VERSION ""

NS_ :

BS_:

BU_: ppt eps_batt eps_dist eps_gen adcs_rwz adcs_rwy adcs_rwx adcs_mtq rahs adcs_sensorproc adcs_mpc adcs_estim adcs_bdot com_1 com_2
VAL_TABLE_ mtq_phase 2 "pms_phase" 1 "actuation_phase" 0 "measurement_phase" ;
VAL_TABLE_ bdot_mag_mode 3 "sp2 mode" 2 "sp1 mode" 1 "bdot mode" 0 "auto mode" ;
VAL_TABLE_ bdot_control_mode 3 "spam" 2 "spam mag self test" 1 "sleep mode" 0 "normal mode" ;
VAL_TABLE_ domain_state 3 "off_batt_undervoltage" 2 "off_overcurrent" 1 "off_manual" 0 "on" ;
VAL_TABLE_ nbool 2 "null" 1 "true" 0 "false" ;
VAL_TABLE_ fire_state 3 "no discharge" 2 "no charge" 1 "fire overridden" 0 "fire successful" ;
VAL_TABLE_ uv_state 1 "undervoltage" 0 "normal" ;
VAL_TABLE_ mode 4 "low power" 3 "pointing" 1 "bdot" 0 "fsw off" ;
VAL_TABLE_ pwr_domain 8 "unk" 7 "com1" 6 "com2" 5 "rahs" 4 "bdot" 3 "estim" 2 "wheel" 1 "eps" 0 "ppt" ;
VAL_TABLE_ sat_state 1 "good" 0 "bad" ;
VAL_TABLE_ node 15 "rahs" 14 "com_2" 13 "com_1" 12 "adcs_mtq" 11 "adcs_sensorproc" 10 "adcs_mpc" 9 "adcs_estim" 8 "eps_batt" 7 "eps_gen" 6 "eps_dist" 5 "ppt" 4 "adcs_rwz" 3 "adcs_rwy" 2 "adcs_rwx" 1 "adcs_bdot" 0 "test" ;
VAL_TABLE_ agg 5 "sum" 4 "max" 3 "min" 2 "count" 1 "avg" 0 "none" ;
VAL_TABLE_ bool 1 "true" 0 "false" ;

BO_ 2449736399 gcmd_eps_batt_fulldef: 8 Vector__XXX
 SG_ gcmd_eps_batt_fulldef_const_volt : 0|32@1- (1,0) [0|8] "V" Vector__XXX
 SG_ gcmd_eps_batt_fulldef_chg_curr : 32|32@1- (1,0) [0|1] "Amps" Vector__XXX

BO_ 2452161116 rc_adcs_bdot_5: 6 Vector__XXX
 SG_ rc_adcs_bdot_5_last_spam_z_mtq_z : 32|16@1- (1,0) [-32768|32767] "1/73 nT" Vector__XXX
 SG_ rc_adcs_bdot_5_last_spam_z_mtq_y : 16|16@1- (1,0) [-32768|32767] "1/73 nT" Vector__XXX
 SG_ rc_adcs_bdot_5_last_spam_z_mtq_x : 0|16@1- (1,0) [-32768|32767] "1/73 nT" Vector__XXX

BO_ 2449736398 gcmd_reset_minmax: 0 Vector__XXX

BO_ 2452161134 rc_eps_batt_h2: 1 Vector__XXX
 SG_ rc_eps_batt_h2_canrxerror : 0|8@1+ (1,0) [0|255] "" Vector__XXX

BO_ 2452161133 rc_adcs_bdot_h2: 1 Vector__XXX
 SG_ rc_adcs_bdot_h2_canrxerror : 0|8@1+ (1,0) [0|255] "" Vector__XXX

BO_ 2452161132 rc_eps_dist_h2: 1 Vector__XXX
 SG_ rc_eps_dist_h2_canrxerror : 0|8@1+ (1,0) [0|255] "" Vector__XXX

BO_ 2452161131 rc_adcs_mpc_h2: 8 Vector__XXX
 SG_ rc_adcs_mpc_h2_canrxerror : 0|8@1+ (1,0) [0|255] "" Vector__XXX

BO_ 2452161130 rc_adcs_estim_h2: 1 Vector__XXX
 SG_ rc_adcs_estim_h2_canrxerror : 0|8@1+ (1,0) [0|255] "" Vector__XXX

BO_ 2452161129 rc_adcs_sp_h2: 1 Vector__XXX
 SG_ rc_adcs_sp_h2_canrxerror : 0|8@1+ (1,0) [0|255] "" Vector__XXX

BO_ 2452161128 rc_eps_gen_h2: 8 Vector__XXX
 SG_ rc_eps_gen_h2_canrxerror : 0|8@1+ (1,0) [0|255] "" Vector__XXX

BO_ 2452161127 rc_adcs_mtq_h2: 1 Vector__XXX
 SG_ rc_adcs_mtq_h2_canrxerror : 0|8@1+ (1,0) [0|255] "" Vector__XXX

BO_ 2452161126 rc_ppt_h2: 1 Vector__XXX
 SG_ rc_ppt_h2_canrxerror : 0|8@1+ (1,0) [0|255] "" Vector__XXX

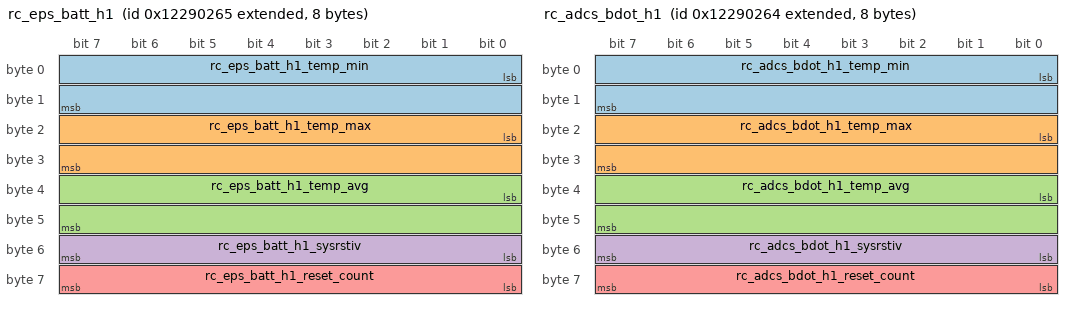
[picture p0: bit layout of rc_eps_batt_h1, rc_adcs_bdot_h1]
BO_ 2452161125 rc_eps_batt_h1: 8 Vector__XXX
 SG_ rc_eps_batt_h1_temp_min : 0|16@1- (1,0) [-32768|32767] "cC" Vector__XXX
 SG_ rc_eps_batt_h1_temp_max : 16|16@1- (1,0) [-32768|32767] "cC" Vector__XXX
 SG_ rc_eps_batt_h1_temp_avg : 32|16@1- (1,0) [-32768|32767] "cC" Vector__XXX
 SG_ rc_eps_batt_h1_sysrstiv : 48|8@1+ (1,0) [0|255] "" Vector__XXX
 SG_ rc_eps_batt_h1_reset_count : 56|8@1+ (1,0) [0|255] "" Vector__XXX

BO_ 2452161124 rc_adcs_bdot_h1: 8 Vector__XXX
 SG_ rc_adcs_bdot_h1_temp_min : 0|16@1- (1,0) [-32768|32767] "cC" Vector__XXX
 SG_ rc_adcs_bdot_h1_temp_max : 16|16@1- (1,0) [-32768|32767] "cC" Vector__XXX
 SG_ rc_adcs_bdot_h1_temp_avg : 32|16@1- (1,0) [-32768|32767] "cC" Vector__XXX
 SG_ rc_adcs_bdot_h1_sysrstiv : 48|8@1+ (1,0) [0|255] "" Vector__XXX
 SG_ rc_adcs_bdot_h1_reset_count : 56|8@1+ (1,0) [0|255] "" Vector__XXX

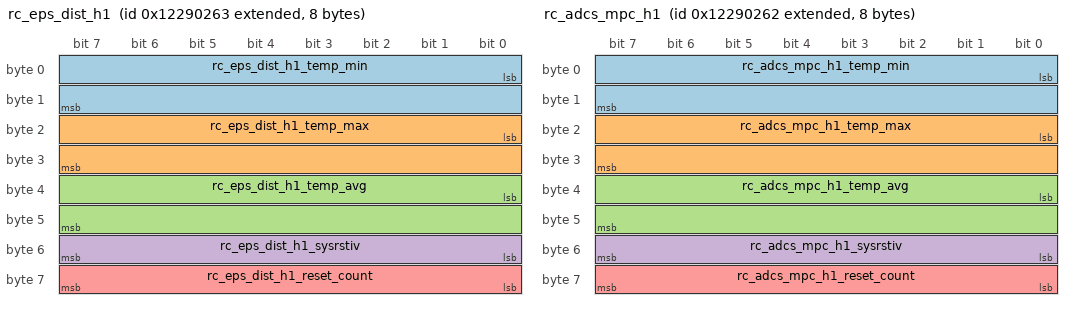
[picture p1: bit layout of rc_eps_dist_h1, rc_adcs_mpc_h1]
BO_ 2452161123 rc_eps_dist_h1: 8 Vector__XXX
 SG_ rc_eps_dist_h1_temp_min : 0|16@1- (1,0) [-32768|32767] "cC" Vector__XXX
 SG_ rc_eps_dist_h1_temp_max : 16|16@1- (1,0) [-32768|32767] "cC" Vector__XXX
 SG_ rc_eps_dist_h1_temp_avg : 32|16@1- (1,0) [-32768|32767] "cC" Vector__XXX
 SG_ rc_eps_dist_h1_sysrstiv : 48|8@1+ (1,0) [0|255] "" Vector__XXX
 SG_ rc_eps_dist_h1_reset_count : 56|8@1+ (1,0) [0|255] "" Vector__XXX

BO_ 2452161122 rc_adcs_mpc_h1: 8 Vector__XXX
 SG_ rc_adcs_mpc_h1_temp_min : 0|16@1- (1,0) [-32768|32767] "cC" Vector__XXX
 SG_ rc_adcs_mpc_h1_temp_max : 16|16@1- (1,0) [-32768|32767] "cC" Vector__XXX
 SG_ rc_adcs_mpc_h1_temp_avg : 32|16@1- (1,0) [-32768|32767] "cC" Vector__XXX
 SG_ rc_adcs_mpc_h1_sysrstiv : 48|8@1+ (1,0) [0|255] "" Vector__XXX
 SG_ rc_adcs_mpc_h1_reset_count : 56|8@1+ (1,0) [0|255] "" Vector__XXX

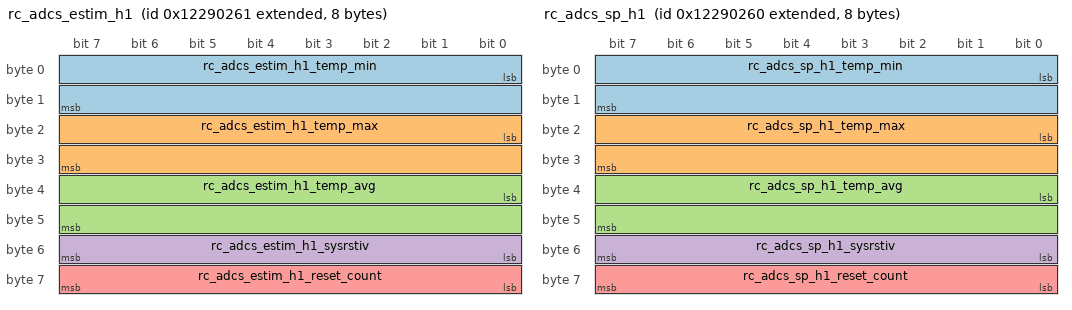
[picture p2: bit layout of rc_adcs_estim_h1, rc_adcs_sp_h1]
BO_ 2452161121 rc_adcs_estim_h1: 8 Vector__XXX
 SG_ rc_adcs_estim_h1_temp_min : 0|16@1- (1,0) [-32768|32767] "cC" Vector__XXX
 SG_ rc_adcs_estim_h1_temp_max : 16|16@1- (1,0) [-32768|32767] "cC" Vector__XXX
 SG_ rc_adcs_estim_h1_temp_avg : 32|16@1- (1,0) [-32768|32767] "cC" Vector__XXX
 SG_ rc_adcs_estim_h1_sysrstiv : 48|8@1+ (1,0) [0|255] "" Vector__XXX
 SG_ rc_adcs_estim_h1_reset_count : 56|8@1+ (1,0) [0|255] "" Vector__XXX

BO_ 2452161120 rc_adcs_sp_h1: 8 Vector__XXX
 SG_ rc_adcs_sp_h1_temp_min : 0|16@1- (1,0) [-32768|32767] "cC" Vector__XXX
 SG_ rc_adcs_sp_h1_temp_max : 16|16@1- (1,0) [-32768|32767] "cC" Vector__XXX
 SG_ rc_adcs_sp_h1_temp_avg : 32|16@1- (1,0) [-32768|32767] "cC" Vector__XXX
 SG_ rc_adcs_sp_h1_sysrstiv : 48|8@1+ (1,0) [0|255] "" Vector__XXX
 SG_ rc_adcs_sp_h1_reset_count : 56|8@1+ (1,0) [0|255] "" Vector__XXX

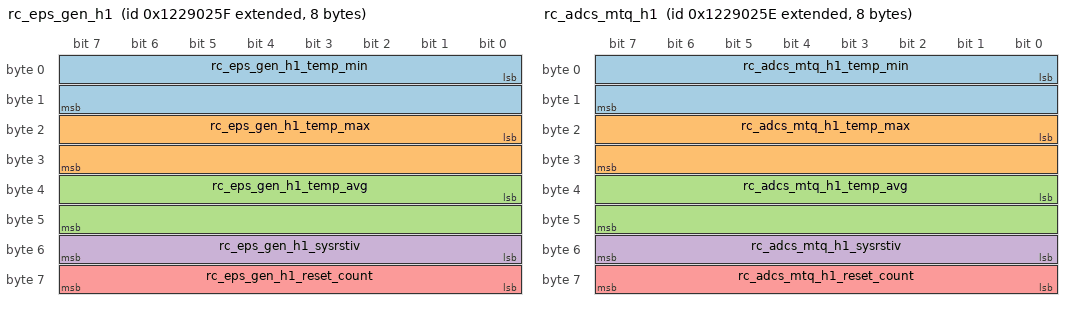
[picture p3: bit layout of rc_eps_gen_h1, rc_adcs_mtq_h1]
BO_ 2452161119 rc_eps_gen_h1: 8 Vector__XXX
 SG_ rc_eps_gen_h1_temp_min : 0|16@1- (1,0) [-32768|32767] "cC" Vector__XXX
 SG_ rc_eps_gen_h1_temp_max : 16|16@1- (1,0) [-32768|32767] "cC" Vector__XXX
 SG_ rc_eps_gen_h1_temp_avg : 32|16@1- (1,0) [-32768|32767] "cC" Vector__XXX
 SG_ rc_eps_gen_h1_sysrstiv : 48|8@1+ (1,0) [0|255] "" Vector__XXX
 SG_ rc_eps_gen_h1_reset_count : 56|8@1+ (1,0) [0|255] "" Vector__XXX

BO_ 2452161118 rc_adcs_mtq_h1: 8 Vector__XXX
 SG_ rc_adcs_mtq_h1_temp_min : 0|16@1- (1,0) [-32768|32767] "cC" Vector__XXX
 SG_ rc_adcs_mtq_h1_temp_max : 16|16@1- (1,0) [-32768|32767] "cC" Vector__XXX
 SG_ rc_adcs_mtq_h1_temp_avg : 32|16@1- (1,0) [-32768|32767] "cC" Vector__XXX
 SG_ rc_adcs_mtq_h1_sysrstiv : 48|8@1+ (1,0) [0|255] "" Vector__XXX
 SG_ rc_adcs_mtq_h1_reset_count : 56|8@1+ (1,0) [0|255] "" Vector__XXX

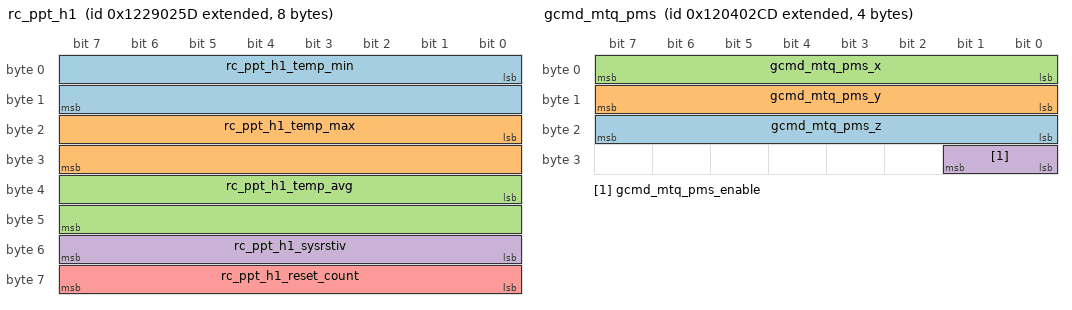
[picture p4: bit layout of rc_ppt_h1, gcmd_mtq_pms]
BO_ 2452161117 rc_ppt_h1: 8 Vector__XXX
 SG_ rc_ppt_h1_temp_min : 0|16@1- (1,0) [-32768|32767] "cC" Vector__XXX
 SG_ rc_ppt_h1_temp_max : 16|16@1- (1,0) [-32768|32767] "cC" Vector__XXX
 SG_ rc_ppt_h1_temp_avg : 32|16@1- (1,0) [-32768|32767] "cC" Vector__XXX
 SG_ rc_ppt_h1_sysrstiv : 48|8@1+ (1,0) [0|255] "" Vector__XXX
 SG_ rc_ppt_h1_reset_count : 56|8@1+ (1,0) [0|255] "" Vector__XXX

BO_ 2449736397 gcmd_mtq_pms: 4 Vector__XXX
 SG_ gcmd_mtq_pms_z : 16|8@1- (1,0) [-100|100] "" Vector__XXX
 SG_ gcmd_mtq_pms_y : 8|8@1- (1,0) [-100|100] "" Vector__XXX
 SG_ gcmd_mtq_pms_x : 0|8@1- (1,0) [-100|100] "" Vector__XXX
 SG_ gcmd_mtq_pms_enable : 24|2@1+ (1,0) [0|2] "" Vector__XXX

BO_ 2449736396 gcmd_bdot_max_tumble: 2 Vector__XXX
 SG_ gcmd_bdot_max_tumble_time : 0|16@1+ (1,0) [0|65535] "minutes" Vector__XXX

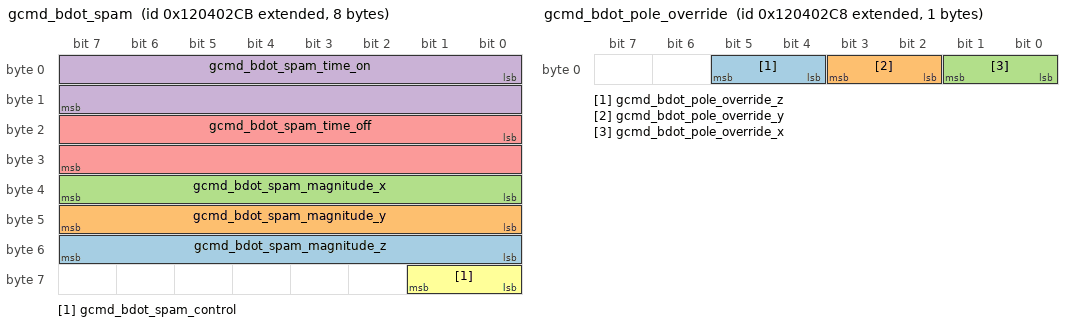
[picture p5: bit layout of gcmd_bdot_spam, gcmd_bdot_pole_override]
BO_ 2449736395 gcmd_bdot_spam: 8 Vector__XXX
 SG_ gcmd_bdot_spam_magnitude_z : 48|8@1- (1,0) [-100|100] "" Vector__XXX
 SG_ gcmd_bdot_spam_magnitude_y : 40|8@1- (1,0) [-100|100] "" Vector__XXX
 SG_ gcmd_bdot_spam_magnitude_x : 32|8@1- (1,0) [-100|100] "" Vector__XXX
 SG_ gcmd_bdot_spam_time_on : 0|16@1+ (1,0) [0|65535] "minutes" Vector__XXX
 SG_ gcmd_bdot_spam_time_off : 16|16@1+ (1,0) [0|65535] "minutes" Vector__XXX
 SG_ gcmd_bdot_spam_control : 56|2@1+ (1,0) [0|2] "" Vector__XXX

BO_ 2449736394 gcmd_bdot_control: 1 Vector__XXX
 SG_ gcmd_bdot_control_mode : 0|2@1+ (1,0) [0|3] "" Vector__XXX

BO_ 2449736393 gcmd_bdot_mag_control: 1 Vector__XXX
 SG_ gcmd_bdot_mag_control_mode : 0|2@1+ (1,0) [0|3] "" Vector__XXX

BO_ 2449736392 gcmd_bdot_pole_override: 1 Vector__XXX
 SG_ gcmd_bdot_pole_override_z : 4|2@1+ (1,0) [0|2] "" Vector__XXX
 SG_ gcmd_bdot_pole_override_y : 2|2@1+ (1,0) [0|2] "" Vector__XXX
 SG_ gcmd_bdot_pole_override_x : 0|2@1+ (1,0) [0|2] "" Vector__XXX

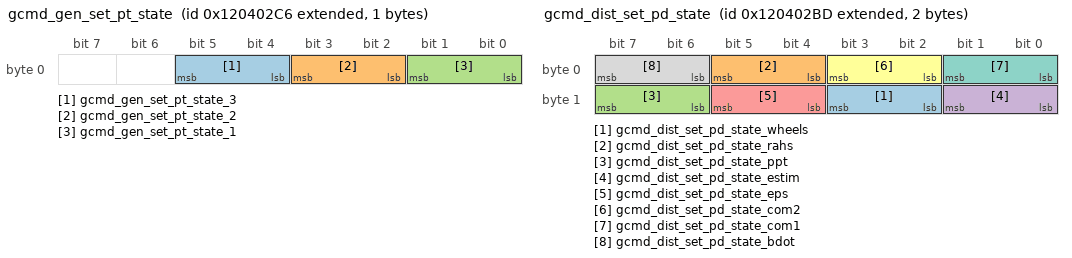
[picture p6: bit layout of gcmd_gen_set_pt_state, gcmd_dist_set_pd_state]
BO_ 2449736390 gcmd_gen_set_pt_state: 1 Vector__XXX
 SG_ gcmd_gen_set_pt_state_3 : 4|2@1+ (1,0) [0|3] "" Vector__XXX
 SG_ gcmd_gen_set_pt_state_2 : 2|2@1+ (1,0) [0|3] "" Vector__XXX
 SG_ gcmd_gen_set_pt_state_1 : 0|2@1+ (1,0) [0|3] "" Vector__XXX

BO_ 2449736391 gcmd_sp_set_thresh: 1 Vector__XXX
 SG_ gcmd_sp_set_thresh_thresh : 0|16@1+ (1,0) [0|65535] "1/73 nanoTeslas" Vector__XXX

BO_ 2449736389 gcmd_dist_set_pd_ovc_ppt: 4 Vector__XXX
 SG_ gcmd_dist_set_pd_ovc_ppt_ovc : 0|32@1- (1,0) [0|15] "A" Vector__XXX

BO_ 2449736388 gcmd_dist_set_pd_ovc_eps: 4 Vector__XXX
 SG_ gcmd_dist_set_pd_ovc_eps_ovc : 0|32@1- (1,0) [0|15] "A" Vector__XXX

BO_ 2449736387 gcmd_dist_set_pd_ovc_wheels: 4 Vector__XXX
 SG_ gcmd_dist_set_pd_ovc_wheels_ovc : 0|32@1- (1,0) [0|15] "A" Vector__XXX

BO_ 2449736386 gcmd_dist_set_pd_ovc_estim: 4 Vector__XXX
 SG_ gcmd_dist_set_pd_ovc_estim_ovc : 0|32@1- (1,0) [0|15] "A" Vector__XXX

BO_ 2449736385 gcmd_dist_set_pd_ovc_bdot: 4 Vector__XXX
 SG_ gcmd_dist_set_pd_ovc_bdot_ovc : 0|32@1- (1,0) [0|15] "A" Vector__XXX

BO_ 2449736384 gcmd_dist_set_pd_ovc_rahs: 4 Vector__XXX
 SG_ gcmd_dist_set_pd_ovc_rahs_ovc : 0|32@1- (1,0) [0|15] "A" Vector__XXX

BO_ 2449736383 gcmd_dist_set_pd_ovc_com2: 4 Vector__XXX
 SG_ gcmd_dist_set_pd_ovc_com2_ovc : 0|32@1- (1,0) [0|15] "A" Vector__XXX

BO_ 2449736382 gcmd_dist_set_pd_ovc_com1: 4 Vector__XXX
 SG_ gcmd_dist_set_pd_ovc_com1_ovc : 0|32@1- (1,0) [0|15] "A" Vector__XXX

BO_ 2449736381 gcmd_dist_set_pd_state: 2 Vector__XXX
 SG_ gcmd_dist_set_pd_state_wheels : 10|2@1+ (1,0) [0|3] "" Vector__XXX
 SG_ gcmd_dist_set_pd_state_rahs : 4|2@1+ (1,0) [0|3] "" Vector__XXX
 SG_ gcmd_dist_set_pd_state_ppt : 14|2@1+ (1,0) [0|3] "" Vector__XXX
 SG_ gcmd_dist_set_pd_state_estim : 8|2@1+ (1,0) [0|3] "" Vector__XXX
 SG_ gcmd_dist_set_pd_state_eps : 12|2@1+ (1,0) [0|3] "" Vector__XXX
 SG_ gcmd_dist_set_pd_state_com2 : 2|2@1+ (1,0) [0|3] "" Vector__XXX
 SG_ gcmd_dist_set_pd_state_com1 : 0|2@1+ (1,0) [0|3] "" Vector__XXX
 SG_ gcmd_dist_set_pd_state_bdot : 6|2@1+ (1,0) [0|3] "" Vector__XXX

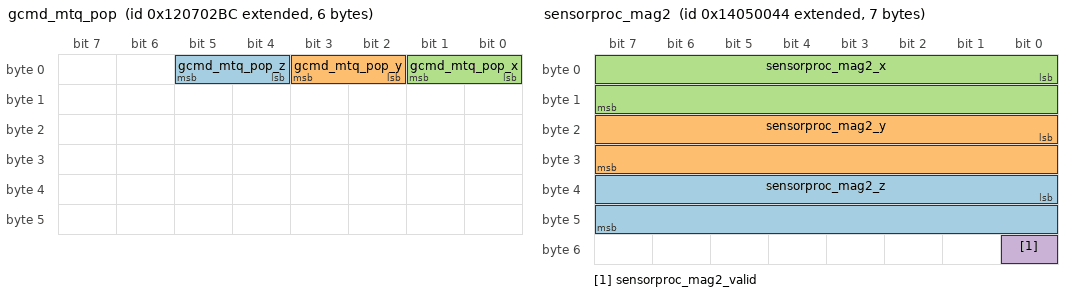
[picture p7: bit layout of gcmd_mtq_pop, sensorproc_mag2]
BO_ 2449932988 gcmd_mtq_pop: 6 Vector__XXX
 SG_ gcmd_mtq_pop_z : 4|2@1+ (1,0) [0|2] "" Vector__XXX
 SG_ gcmd_mtq_pop_y : 2|2@1+ (1,0) [0|2] "" Vector__XXX
 SG_ gcmd_mtq_pop_x : 0|2@1+ (1,0) [0|2] "" Vector__XXX

BO_ 2452161114 rc_eps_batt_7: 6 Vector__XXX
 SG_ rc_eps_batt_7_acc_charge_min : 0|16@1+ (1,0) [0|65535] "22.588 mAh" Vector__XXX
 SG_ rc_eps_batt_7_acc_charge_max : 16|16@1+ (1,0) [0|65535] "22.588 mAh" Vector__XXX
 SG_ rc_eps_batt_7_acc_charge_avg : 32|16@1+ (1,0) [0|65535] "22.588 mAh" Vector__XXX

BO_ 2483355716 sensorproc_mag2: 7 Vector__XXX
 SG_ sensorproc_mag2_z : 32|16@1- (1,0) [-32768|32767] "73 nanoTeslas" Vector__XXX
 SG_ sensorproc_mag2_y : 16|16@1- (1,0) [-32768|32767] "73 nanoTeslas" Vector__XXX
 SG_ sensorproc_mag2_x : 0|16@1- (1,0) [-32768|32767] "73 nanoTeslas" Vector__XXX
 SG_ sensorproc_mag2_valid : 48|1@1+ (1,0) [0|1] "bool" Vector__XXX

BO_ 2452161113 rc_adcs_estim_14: 8 Vector__XXX
 SG_ rc_adcs_estim_14_mag_z : 0|64@1- (1,0) [-1|1] "u" Vector__XXX

BO_ 2452161112 rc_adcs_estim_13: 8 Vector__XXX
 SG_ rc_adcs_estim_13_mag_y : 0|64@1- (1,0) [-1|1] "u" Vector__XXX

BO_ 2452161111 rc_adcs_estim_12: 8 Vector__XXX
 SG_ rc_adcs_estim_12_mag_x : 0|64@1- (1,0) [-1|1] "u" Vector__XXX

BO_ 2452161110 rc_adcs_estim_11: 8 Vector__XXX
 SG_ rc_adcs_estim_11_sun_z : 0|64@1- (1,0) [-1|1] "u" Vector__XXX

BO_ 2452161109 rc_adcs_estim_10: 8 Vector__XXX
 SG_ rc_adcs_estim_10_sun_y : 0|64@1- (1,0) [-1|1] "u" Vector__XXX

BO_ 2452161108 rc_adcs_estim_9: 8 Vector__XXX
 SG_ rc_adcs_estim_9_sun_x : 0|64@1- (1,0) [-1|1] "u" Vector__XXX

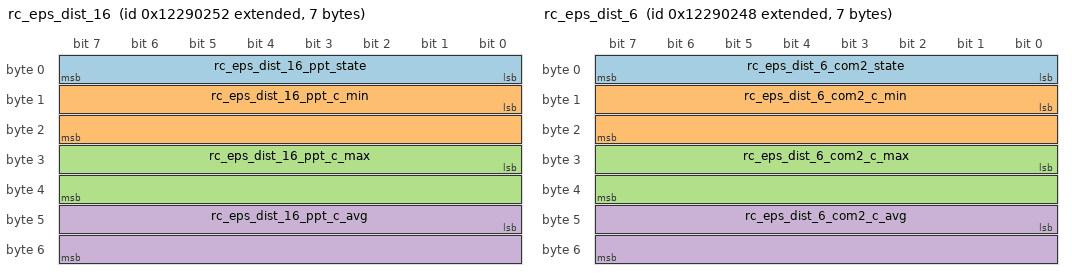
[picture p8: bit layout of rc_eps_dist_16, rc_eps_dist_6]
BO_ 2452161106 rc_eps_dist_16: 7 Vector__XXX
 SG_ rc_eps_dist_16_ppt_state : 0|8@1+ (1,0) [0|3] "" Vector__XXX
 SG_ rc_eps_dist_16_ppt_c_min : 8|16@1- (1,0) [-32768|32767] "raw node current dist" Vector__XXX
 SG_ rc_eps_dist_16_ppt_c_max : 24|16@1- (1,0) [-32768|32767] "raw node current dist" Vector__XXX
 SG_ rc_eps_dist_16_ppt_c_avg : 40|16@1- (1,0) [-32768|32767] "raw node current dist" Vector__XXX

BO_ 2452161099 rc_eps_dist_9: 6 Vector__XXX
 SG_ rc_eps_dist_9_rahs_v_min : 0|16@1+ (1,0) [0|65535] "raw node voltage" Vector__XXX
 SG_ rc_eps_dist_9_rahs_v_max : 16|16@1+ (1,0) [0|65535] "raw node voltage" Vector__XXX
 SG_ rc_eps_dist_9_rahs_v_avg : 32|16@1+ (1,0) [0|65535] "raw node voltage" Vector__XXX

BO_ 2452161097 rc_eps_dist_7: 6 Vector__XXX
 SG_ rc_eps_dist_7_com2_v_min : 0|16@1+ (1,0) [0|65535] "raw node voltage" Vector__XXX
 SG_ rc_eps_dist_7_com2_v_max : 16|16@1+ (1,0) [0|65535] "raw node voltage" Vector__XXX
 SG_ rc_eps_dist_7_com2_v_avg : 32|16@1+ (1,0) [0|65535] "raw node voltage" Vector__XXX

BO_ 2452161096 rc_eps_dist_6: 7 Vector__XXX
 SG_ rc_eps_dist_6_com2_state : 0|8@1+ (1,0) [0|3] "" Vector__XXX
 SG_ rc_eps_dist_6_com2_c_min : 8|16@1- (1,0) [-32768|32767] "raw node current dist" Vector__XXX
 SG_ rc_eps_dist_6_com2_c_max : 24|16@1- (1,0) [-32768|32767] "raw node current dist" Vector__XXX
 SG_ rc_eps_dist_6_com2_c_avg : 40|16@1- (1,0) [-32768|32767] "raw node current dist" Vector__XXX

BO_ 2452161095 rc_eps_dist_5: 6 Vector__XXX
 SG_ rc_eps_dist_5_com1_v_min : 0|16@1+ (1,0) [0|65535] "raw node voltage" Vector__XXX
 SG_ rc_eps_dist_5_com1_v_max : 16|16@1+ (1,0) [0|65535] "raw node voltage" Vector__XXX
 SG_ rc_eps_dist_5_com1_v_avg : 32|16@1+ (1,0) [0|65535] "raw node voltage" Vector__XXX

BO_ 2452161093 rc_eps_dist_3: 6 Vector__XXX
 SG_ rc_eps_dist_3_batt_v_avg : 32|16@1+ (1,0) [0|65535] "raw dist battery voltage" Vector__XXX
 SG_ rc_eps_dist_3_batt_v_max : 16|16@1+ (1,0) [0|65535] "raw dist battery voltage" Vector__XXX
 SG_ rc_eps_dist_3_batt_v_min : 0|16@1+ (1,0) [0|65535] "raw dist battery voltage" Vector__XXX

BO_ 2452161092 rc_eps_dist_2: 6 Vector__XXX
 SG_ rc_eps_dist_2_uv_state : 0|8@1+ (1,0) [0|3] "" Vector__XXX
 SG_ rc_eps_dist_2_met_overflow : 40|8@1+ (1,0) [0|255] "" Vector__XXX
 SG_ rc_eps_dist_2_met : 8|32@1+ (1,0) [0|4294967296] "2^-8 s" Vector__XXX

BO_ 2452161107 rc_eps_dist_17: 6 Vector__XXX
 SG_ rc_eps_dist_17_ppt_v_min : 0|16@1+ (1,0) [0|65535] "raw node voltage" Vector__XXX
 SG_ rc_eps_dist_17_ppt_v_max : 16|16@1+ (1,0) [0|65535] "raw node voltage" Vector__XXX
 SG_ rc_eps_dist_17_ppt_v_avg : 32|16@1+ (1,0) [0|65535] "raw node voltage" Vector__XXX

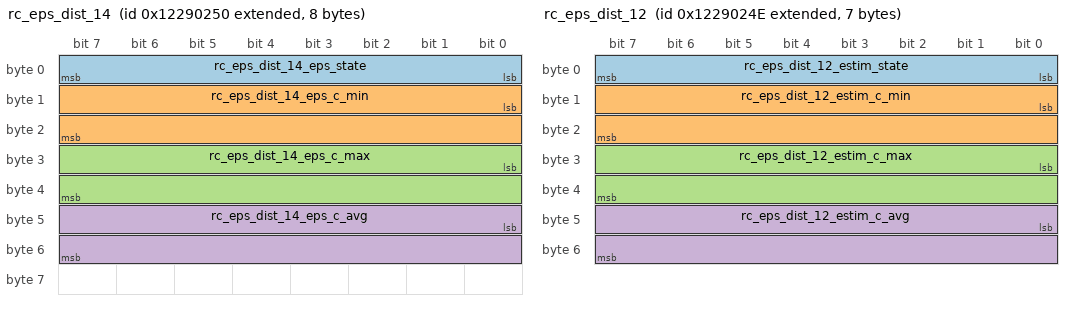
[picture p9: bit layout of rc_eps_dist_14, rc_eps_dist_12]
BO_ 2452161104 rc_eps_dist_14: 8 Vector__XXX
 SG_ rc_eps_dist_14_eps_state : 0|8@1+ (1,0) [0|3] "" Vector__XXX
 SG_ rc_eps_dist_14_eps_c_min : 8|16@1- (1,0) [-32768|32767] "raw node current dist" Vector__XXX
 SG_ rc_eps_dist_14_eps_c_max : 24|16@1- (1,0) [-32768|32767] "raw node current dist" Vector__XXX
 SG_ rc_eps_dist_14_eps_c_avg : 40|16@1- (1,0) [-32768|32767] "raw node current dist" Vector__XXX

BO_ 2452161103 rc_eps_dist_13: 6 Vector__XXX
 SG_ rc_eps_dist_13_estim_v_min : 0|16@1+ (1,0) [0|65535] "raw node voltage" Vector__XXX
 SG_ rc_eps_dist_13_estim_v_max : 16|16@1+ (1,0) [0|65535] "raw node voltage" Vector__XXX
 SG_ rc_eps_dist_13_estim_v_avg : 32|16@1+ (1,0) [0|65535] "raw node voltage" Vector__XXX

BO_ 2452161101 rc_eps_dist_11: 6 Vector__XXX
 SG_ rc_eps_dist_11_bdot_v_min : 0|16@1+ (1,0) [0|65535] "raw node voltage" Vector__XXX
 SG_ rc_eps_dist_11_bdot_v_max : 16|16@1+ (1,0) [0|65535] "raw node voltage" Vector__XXX
 SG_ rc_eps_dist_11_bdot_v_avg : 32|16@1+ (1,0) [0|65535] "raw node voltage" Vector__XXX

BO_ 2452161102 rc_eps_dist_12: 7 Vector__XXX
 SG_ rc_eps_dist_12_estim_state : 0|8@1+ (1,0) [0|3] "" Vector__XXX
 SG_ rc_eps_dist_12_estim_c_min : 8|16@1- (1,0) [-32768|32767] "raw node current dist" Vector__XXX
 SG_ rc_eps_dist_12_estim_c_max : 24|16@1- (1,0) [-32768|32767] "raw node current dist" Vector__XXX
 SG_ rc_eps_dist_12_estim_c_avg : 40|16@1- (1,0) [-32768|32767] "raw node current dist" Vector__XXX

BO_ 2452161105 rc_eps_dist_15: 6 Vector__XXX
 SG_ rc_eps_dist_15_eps_v_min : 0|16@1+ (1,0) [0|65535] "raw node voltage" Vector__XXX
 SG_ rc_eps_dist_15_eps_v_max : 16|16@1+ (1,0) [0|65535] "raw node voltage" Vector__XXX
 SG_ rc_eps_dist_15_eps_v_avg : 32|16@1+ (1,0) [0|65535] "raw node voltage" Vector__XXX

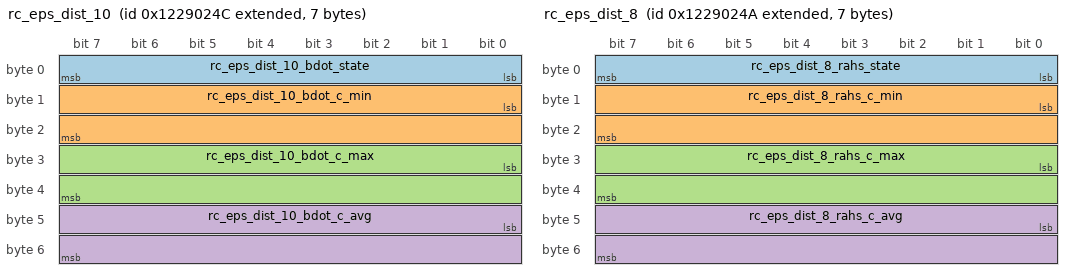
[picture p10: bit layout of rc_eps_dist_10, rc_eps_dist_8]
BO_ 2452161100 rc_eps_dist_10: 7 Vector__XXX
 SG_ rc_eps_dist_10_bdot_state : 0|8@1+ (1,0) [0|3] "" Vector__XXX
 SG_ rc_eps_dist_10_bdot_c_min : 8|16@1- (1,0) [-32768|32767] "raw node current dist" Vector__XXX
 SG_ rc_eps_dist_10_bdot_c_max : 24|16@1- (1,0) [-32768|32767] "raw node current dist" Vector__XXX
 SG_ rc_eps_dist_10_bdot_c_avg : 40|16@1- (1,0) [-32768|32767] "raw node current dist" Vector__XXX

BO_ 2452161098 rc_eps_dist_8: 7 Vector__XXX
 SG_ rc_eps_dist_8_rahs_state : 0|8@1+ (1,0) [0|3] "" Vector__XXX
 SG_ rc_eps_dist_8_rahs_c_min : 8|16@1- (1,0) [-32768|32767] "raw node current dist" Vector__XXX
 SG_ rc_eps_dist_8_rahs_c_max : 24|16@1- (1,0) [-32768|32767] "raw node current dist" Vector__XXX
 SG_ rc_eps_dist_8_rahs_c_avg : 40|16@1- (1,0) [-32768|32767] "raw node current dist" Vector__XXX

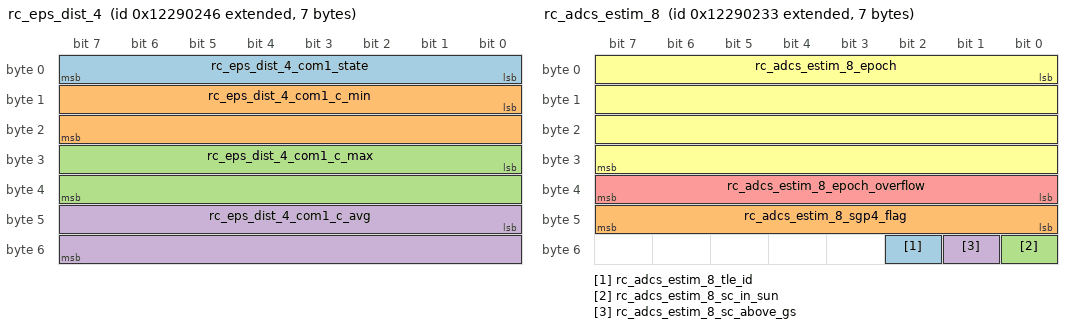
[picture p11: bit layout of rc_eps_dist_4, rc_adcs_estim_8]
BO_ 2452161094 rc_eps_dist_4: 7 Vector__XXX
 SG_ rc_eps_dist_4_com1_state : 0|8@1+ (1,0) [0|3] "" Vector__XXX
 SG_ rc_eps_dist_4_com1_c_min : 8|16@1- (1,0) [-32768|32767] "raw node current dist" Vector__XXX
 SG_ rc_eps_dist_4_com1_c_max : 24|16@1- (1,0) [-32768|32767] "raw node current dist" Vector__XXX
 SG_ rc_eps_dist_4_com1_c_avg : 40|16@1- (1,0) [-32768|32767] "raw node current dist" Vector__XXX

BO_ 2452161091 rc_eps_dist_1: 8 Vector__XXX

BO_ 2452161086 rc_adcs_mpc_11: 8 Vector__XXX
 SG_ rc_adcs_mpc_11_omega_z : 0|64@1- (1,0) [-10|10] "r/s" Vector__XXX

BO_ 2452161082 rc_adcs_mpc_7: 8 Vector__XXX
 SG_ rc_adcs_mpc_7_omega_max : 0|64@1- (1,0) [0|10] "r/s" Vector__XXX

BO_ 2452161083 rc_adcs_mpc_8: 8 Vector__XXX
 SG_ rc_adcs_mpc_8_omega_avg : 0|64@1- (1,0) [0|10] "r/s" Vector__XXX

BO_ 2452161084 rc_adcs_mpc_9: 8 Vector__XXX
 SG_ rc_adcs_mpc_9_omega_x : 0|64@1- (1,0) [-10|10] "r/s" Vector__XXX

BO_ 2452161080 rc_adcs_mpc_5: 8 Vector__XXX
 SG_ rc_adcs_mpc_5_sc_quat_4 : 0|64@1- (1,0) [-1|1] "u" Vector__XXX

BO_ 2452161081 rc_adcs_mpc_6: 8 Vector__XXX
 SG_ rc_adcs_mpc_6_omega_min : 0|64@1- (1,0) [0|10] "r/s" Vector__XXX

BO_ 2452161079 rc_adcs_mpc_4: 8 Vector__XXX
 SG_ rc_adcs_mpc_4_sc_quat_3 : 0|64@1- (1,0) [-1|1] "u" Vector__XXX

BO_ 2452161078 rc_adcs_mpc_3: 8 Vector__XXX
 SG_ rc_adcs_mpc_3_sc_quat_2 : 0|64@1- (1,0) [-1|1] "u" Vector__XXX

BO_ 2452161090 rc_adcs_mpc_15: 2 Vector__XXX
 SG_ rc_adcs_mpc_15_sc_mode : 0|8@1+ (1,0) [0|32] "" Vector__XXX
 SG_ rc_adcs_mpc_15_point_true : 8|8@1+ (1,0) [0|255] "" Vector__XXX

BO_ 2452161087 rc_adcs_mpc_12: 8 Vector__XXX

BO_ 2452161088 rc_adcs_mpc_13: 8 Vector__XXX

BO_ 2452161089 rc_adcs_mpc_14: 8 Vector__XXX

BO_ 2452161085 rc_adcs_mpc_10: 8 Vector__XXX
 SG_ rc_adcs_mpc_10_omega_y : 0|64@1- (1,0) [-10|10] "r/s" Vector__XXX

BO_ 2452161077 rc_adcs_mpc_2: 8 Vector__XXX
 SG_ rc_adcs_mpc_2_sc_quat_1 : 0|64@1- (1,0) [-1|1] "u" Vector__XXX

BO_ 2452161076 rc_adcs_mpc_1: 8 Vector__XXX

BO_ 2452161075 rc_adcs_estim_8: 7 Vector__XXX
 SG_ rc_adcs_estim_8_tle_id : 50|1@1+ (1,0) [0|1] "" Vector__XXX
 SG_ rc_adcs_estim_8_sgp4_flag : 40|8@1- (1,0) [-1|1] "" Vector__XXX
 SG_ rc_adcs_estim_8_sc_in_sun : 48|1@1+ (1,0) [0|1] "" Vector__XXX
 SG_ rc_adcs_estim_8_sc_above_gs : 49|1@1+ (1,0) [0|1] "" Vector__XXX
 SG_ rc_adcs_estim_8_epoch_overflow : 32|8@1+ (1,0) [0|255] "" Vector__XXX
 SG_ rc_adcs_estim_8_epoch : 0|32@1+ (1,0) [0|4294967295] "2^-8 s" Vector__XXX

BO_ 2452161074 rc_adcs_estim_7: 8 Vector__XXX
 SG_ rc_adcs_estim_7_vel_z : 0|64@1- (1,0) [-1.7E+308|1.7E+308] "m/s" Vector__XXX

BO_ 2452161073 rc_adcs_estim_6: 8 Vector__XXX
 SG_ rc_adcs_estim_6_vel_y : 0|64@1- (1,0) [-1.7E+308|1.7E+308] "m/s" Vector__XXX

BO_ 2452161072 rc_adcs_estim_5: 8 Vector__XXX
 SG_ rc_adcs_estim_5_vel_x : 0|64@1- (1,0) [-1.7E+308|1.7E+308] "m/s" Vector__XXX

BO_ 2452161071 rc_adcs_estim_4: 8 Vector__XXX
 SG_ rc_adcs_estim_4_pos_z : 0|64@1- (1,0) [-7000000|7000000] "m" Vector__XXX

BO_ 2452161069 rc_adcs_estim_2: 8 Vector__XXX
 SG_ rc_adcs_estim_2_pos_x : 0|64@1- (1,0) [-7000000|7000000] "m" Vector__XXX

BO_ 2452161070 rc_adcs_estim_3: 8 Vector__XXX
 SG_ rc_adcs_estim_3_pos_y : 0|64@1- (1,0) [-7000000|7000000] "m" Vector__XXX

BO_ 2452161068 rc_adcs_estim_1: 8 Vector__XXX

BO_ 2452161062 rc_adcs_sp_12: 8 Vector__XXX
 SG_ rc_adcs_sp_12_mag2_z_min : 32|16@1- (1,0) [-32768|32767] "73 nanoTeslas" Vector__XXX
 SG_ rc_adcs_sp_12_mag2_z_max : 48|16@1- (1,0) [-32768|32767] "73 nanoTeslas" Vector__XXX
 SG_ rc_adcs_sp_12_mag2_y_max : 0|16@1- (1,0) [-32768|32767] "73 nanoTeslas" Vector__XXX
 SG_ rc_adcs_sp_12_mag2_y_avg : 16|16@1- (1,0) [-32768|32767] "73 nanoTeslas" Vector__XXX

BO_ 2452161061 rc_adcs_sp_11: 8 Vector__XXX
 SG_ rc_adcs_sp_11_mag2_x_avg : 32|16@1- (1,0) [-32768|32767] "73 nanoTeslas" Vector__XXX
 SG_ rc_adcs_sp_11_mag2_x_max : 16|16@1- (1,0) [-32768|32767] "73 nanoTeslas" Vector__XXX
 SG_ rc_adcs_sp_11_mag2_x_min : 0|16@1- (1,0) [-32768|32767] "73 nanoTeslas" Vector__XXX
 SG_ rc_adcs_sp_11_mag2_y_min : 48|16@1- (1,0) [-32768|32767] "73 nanoTeslas" Vector__XXX

BO_ 2452161057 rc_adcs_sp_7: 8 Vector__XXX

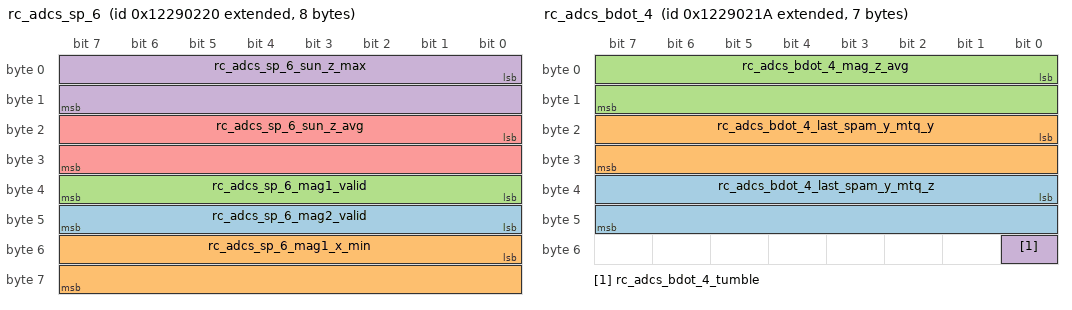
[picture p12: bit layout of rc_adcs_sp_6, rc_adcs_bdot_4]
BO_ 2452161056 rc_adcs_sp_6: 8 Vector__XXX
 SG_ rc_adcs_sp_6_mag2_valid : 40|8@1+ (1,0) [0|255] "" Vector__XXX
 SG_ rc_adcs_sp_6_mag1_x_min : 48|16@1- (1,0) [-32768|32767] "73 nanoTeslas" Vector__XXX
 SG_ rc_adcs_sp_6_mag1_valid : 32|8@1+ (1,0) [0|255] "" Vector__XXX
 SG_ rc_adcs_sp_6_sun_z_max : 0|16@1- (1,0) [-32768|32767] "1/32768 units" Vector__XXX
 SG_ rc_adcs_sp_6_sun_z_avg : 16|16@1- (1,0) [-32768|32767] "1/32768 units" Vector__XXX

BO_ 2452161067 rc_adcs_sp_17: 8 Vector__XXX
 SG_ rc_adcs_sp_17_imu_z_max : 0|16@1- (1,0) [-32768|32767] "0.004375 deg/s" Vector__XXX
 SG_ rc_adcs_sp_17_imu_z_avg : 16|16@1- (1,0) [-32768|32767] "0.004375 deg/s" Vector__XXX

BO_ 2452161066 rc_adcs_sp_16: 8 Vector__XXX
 SG_ rc_adcs_sp_16_imu_z_min : 48|16@1- (1,0) [-32768|32767] "0.004375 deg/s" Vector__XXX
 SG_ rc_adcs_sp_16_imu_y_min : 0|16@1- (1,0) [-32768|32767] "0.004375 deg/s" Vector__XXX
 SG_ rc_adcs_sp_16_imu_y_max : 16|16@1- (1,0) [-32768|32767] "0.004375 deg/s" Vector__XXX
 SG_ rc_adcs_sp_16_imu_y_avg : 32|16@1- (1,0) [-32768|32767] "0.004375 deg/s" Vector__XXX

BO_ 2452161060 rc_adcs_sp_10: 8 Vector__XXX
 SG_ rc_adcs_sp_10_mag1_z_min : 16|16@1- (1,0) [-32768|32767] "73 nanoTeslas" Vector__XXX
 SG_ rc_adcs_sp_10_mag1_z_max : 32|16@1- (1,0) [-32768|32767] "73 nanoTeslas" Vector__XXX
 SG_ rc_adcs_sp_10_mag1_z_avg : 48|16@1- (1,0) [-32768|32767] "73 nanoTeslas" Vector__XXX
 SG_ rc_adcs_sp_10_mag1_y_avg : 0|16@1- (1,0) [-32768|32767] "73 nanoTeslas" Vector__XXX

BO_ 2452161058 rc_adcs_sp_8: 8 Vector__XXX

BO_ 2452161059 rc_adcs_sp_9: 8 Vector__XXX
 SG_ rc_adcs_sp_9_mag1_y_min : 32|16@1- (1,0) [-32768|32767] "73 nanoTeslas" Vector__XXX
 SG_ rc_adcs_sp_9_mag1_y_max : 48|16@1- (1,0) [-32768|32767] "73 nanoTeslas" Vector__XXX
 SG_ rc_adcs_sp_9_mag1_x_max : 0|16@1- (1,0) [-32768|32767] "73 nanoTeslas" Vector__XXX
 SG_ rc_adcs_sp_9_mag1_x_avg : 16|16@1- (1,0) [-32768|32767] "73 nanoTeslas" Vector__XXX

BO_ 2452161063 rc_adcs_sp_13: 8 Vector__XXX
 SG_ rc_adcs_sp_13_suna_min : 16|16@1- (1,0) [-32768|32767] "60/32767 degrees" Vector__XXX
 SG_ rc_adcs_sp_13_suna_max : 32|16@1- (1,0) [-32768|32767] "60/32767 degrees" Vector__XXX
 SG_ rc_adcs_sp_13_suna_avg : 48|16@1- (1,0) [-32768|32767] "60/32767 degrees" Vector__XXX
 SG_ rc_adcs_sp_13_mag2_z_avg : 0|16@1- (1,0) [-32768|32767] "73 nanoTeslas" Vector__XXX

BO_ 2452161065 rc_adcs_sp_15: 8 Vector__XXX
 SG_ rc_adcs_sp_15_imu_x_min : 8|16@1- (1,0) [-32768|32767] "0.004375 deg/s" Vector__XXX
 SG_ rc_adcs_sp_15_imu_x_max : 24|16@1- (1,0) [-32768|32767] "0.004375 deg/s" Vector__XXX
 SG_ rc_adcs_sp_15_imu_x_avg : 40|16@1- (1,0) [-32768|32767] "0.004375 deg/s" Vector__XXX
 SG_ rc_adcs_sp_15_imu_valid : 0|8@1+ (1,0) [0|255] "" Vector__XXX

BO_ 2452161064 rc_adcs_sp_14: 7 Vector__XXX
 SG_ rc_adcs_sp_14_sunb_min : 0|16@1- (1,0) [-32768|32767] "60/32767 degrees" Vector__XXX
 SG_ rc_adcs_sp_14_sunb_max : 16|16@1- (1,0) [-32768|32767] "60/32767 degrees" Vector__XXX
 SG_ rc_adcs_sp_14_sunb_avg : 32|16@1- (1,0) [-32768|32767] "60/32767 degrees" Vector__XXX
 SG_ rc_adcs_sp_14_sun_valid : 48|8@1+ (1,0) [0|255] "" Vector__XXX

BO_ 2452161055 rc_adcs_sp_5: 8 Vector__XXX
 SG_ rc_adcs_sp_5_sun_z_min : 48|16@1- (1,0) [-32768|32767] "1/32768 units" Vector__XXX
 SG_ rc_adcs_sp_5_sun_y_min : 0|16@1- (1,0) [-32768|32767] "1/32768 units" Vector__XXX
 SG_ rc_adcs_sp_5_sun_y_max : 16|16@1- (1,0) [-32768|32767] "1/32768 units" Vector__XXX
 SG_ rc_adcs_sp_5_sun_y_avg : 32|16@1- (1,0) [-32768|32767] "1/32768 units" Vector__XXX

BO_ 2452161054 rc_adcs_sp_4: 8 Vector__XXX
 SG_ rc_adcs_sp_4_sun_x_min : 16|16@1- (1,0) [-32768|32767] "1/32768 units" Vector__XXX
 SG_ rc_adcs_sp_4_sun_x_max : 32|16@1- (1,0) [-32768|32767] "1/32768 units" Vector__XXX
 SG_ rc_adcs_sp_4_sun_x_avg : 48|16@1- (1,0) [-32768|32767] "1/32768 units" Vector__XXX
 SG_ rc_adcs_sp_4_imup_z_avg : 0|16@1- (1,0) [-32768|32767] "0.004375 deg/s" Vector__XXX

BO_ 2452161053 rc_adcs_sp_3: 8 Vector__XXX
 SG_ rc_adcs_sp_3_imup_z_min : 32|16@1- (1,0) [-32768|32767] "0.004375 deg/s" Vector__XXX
 SG_ rc_adcs_sp_3_imup_z_max : 48|16@1- (1,0) [-32768|32767] "0.004375 deg/s" Vector__XXX
 SG_ rc_adcs_sp_3_imup_y_max : 0|16@1- (1,0) [-32768|32767] "0.004375 deg/s" Vector__XXX
 SG_ rc_adcs_sp_3_imup_y_avg : 16|16@1- (1,0) [-32768|32767] "0.004375 deg/s" Vector__XXX

BO_ 2452161052 rc_adcs_sp_2: 8 Vector__XXX
 SG_ rc_adcs_sp_2_imup_y_min : 48|16@1- (1,0) [-32768|32767] "0.004375 deg/s" Vector__XXX
 SG_ rc_adcs_sp_2_imup_x_min : 0|16@1- (1,0) [-32768|32767] "0.004375 deg/s" Vector__XXX
 SG_ rc_adcs_sp_2_imup_x_max : 16|16@1- (1,0) [-32768|32767] "0.004375 deg/s" Vector__XXX
 SG_ rc_adcs_sp_2_imup_x_avg : 32|16@1- (1,0) [-32768|32767] "0.004375 deg/s" Vector__XXX

BO_ 2452161051 rc_adcs_sp_1: 8 Vector__XXX

BO_ 2452161050 rc_adcs_bdot_4: 7 Vector__XXX
 SG_ rc_adcs_bdot_4_last_spam_y_mtq_z : 32|16@1- (1,0) [-32768|32767] "1/73 nT" Vector__XXX
 SG_ rc_adcs_bdot_4_last_spam_y_mtq_y : 16|16@1- (1,0) [-32768|32767] "1/73 nT" Vector__XXX
 SG_ rc_adcs_bdot_4_mag_z_avg : 0|16@1- (1,0) [-32768|32767] "1/73 nT" Vector__XXX
 SG_ rc_adcs_bdot_4_tumble : 48|1@1+ (1,0) [0|1] "" Vector__XXX

BO_ 2452161049 rc_adcs_bdot_3: 8 Vector__XXX
 SG_ rc_adcs_bdot_3_mag_z_min : 32|16@1- (1,0) [-32768|32767] "1/73 nT" Vector__XXX
 SG_ rc_adcs_bdot_3_mag_z_max : 48|16@1- (1,0) [-32768|32767] "1/73 nT" Vector__XXX
 SG_ rc_adcs_bdot_3_mag_y_max : 0|16@1- (1,0) [-32768|32767] "1/73 nT" Vector__XXX
 SG_ rc_adcs_bdot_3_mag_y_avg : 16|16@1- (1,0) [-32768|32767] "1/73 nT" Vector__XXX

BO_ 2452161031 rc_adcs_bdot_2: 8 Vector__XXX
 SG_ rc_adcs_bdot_2_mag_y_min : 48|16@1- (1,0) [-32768|32767] "1/73 nT" Vector__XXX
 SG_ rc_adcs_bdot_2_mag_x_avg : 32|16@1- (1,0) [-32768|32767] "1/73 nT" Vector__XXX
 SG_ rc_adcs_bdot_2_mag_x_min : 0|16@1- (1,0) [-32768|32767] "1/73 nT" Vector__XXX
 SG_ rc_adcs_bdot_2_mag_x_max : 16|16@1- (1,0) [-32768|32767] "1/73 nT" Vector__XXX

BO_ 2452161030 rc_adcs_bdot_1: 8 Vector__XXX
 SG_ rc_adcs_bdot_1_last_spam_y_mtq_x : 48|16@1- (1,0) [-32768|32767] "1/73 nT" Vector__XXX
 SG_ rc_adcs_bdot_1_last_spam_x_mtq_z : 32|16@1- (1,0) [-32768|32767] "1/73 nT" Vector__XXX
 SG_ rc_adcs_bdot_1_last_spam_x_mtq_y : 16|16@1- (1,0) [-32768|32767] "1/73 nT" Vector__XXX
 SG_ rc_adcs_bdot_1_last_spam_x_mtq_x : 0|16@1- (1,0) [-32768|32767] "1/73 nT" Vector__XXX

BO_ 2449932980 estim_sun_unit_z: 8 Vector__XXX
 SG_ estim_sun_unit_z_val : 0|64@1- (1,0) [-1.7E+308|1.7E+308] "u" Vector__XXX

BO_ 2449932979 estim_sun_unit_y: 8 Vector__XXX
 SG_ estim_sun_unit_y_val : 0|64@1- (1,0) [-1.7E+308|1.7E+308] "u" Vector__XXX

BO_ 2449932978 estim_sun_unit_x: 8 Vector__XXX
 SG_ estim_sun_unit_x_val : 0|64@1- (1,0) [-1.7E+308|1.7E+308] "u" Vector__XXX

BO_ 2449932983 estim_mag_unit_z: 8 Vector__XXX
 SG_ estim_mag_unit_z_val : 0|64@1- (1,0) [-1.7E+308|1.7E+308] "u" Vector__XXX

BO_ 2449932982 estim_mag_unit_y: 8 Vector__XXX
 SG_ estim_mag_unit_y_val : 0|64@1- (1,0) [-1.7E+308|1.7E+308] "u" Vector__XXX

BO_ 2449932981 estim_mag_unit_x: 8 Vector__XXX
 SG_ estim_mag_unit_x_val : 0|64@1- (1,0) [-1.7E+308|1.7E+308] "u" Vector__XXX

BO_ 2449932984 estim_state: 1 Vector__XXX
 SG_ estim_state_in_sun : 1|1@1+ (1,0) [0|1] "" Vector__XXX
 SG_ estim_state_above_gs : 0|1@1+ (1,0) [0|1] "" Vector__XXX

BO_ 2452161039 rc_adcs_mtq_5: 2 Vector__XXX
 SG_ rc_adcs_mtq_5_reset_counts : 8|8@1+ (1,0) [0|255] "" Vector__XXX
 SG_ rc_adcs_mtq_5_fsw_ignore : 0|8@1+ (1,0) [0|255] "" Vector__XXX

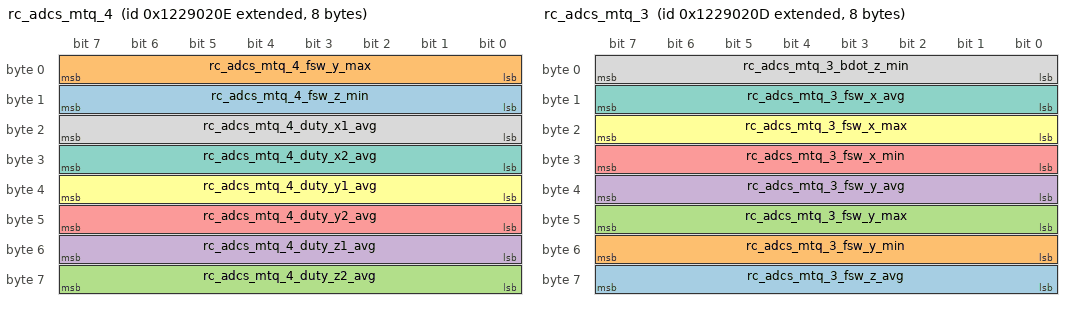
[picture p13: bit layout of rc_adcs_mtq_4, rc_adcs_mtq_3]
BO_ 2452161038 rc_adcs_mtq_4: 8 Vector__XXX
 SG_ rc_adcs_mtq_4_fsw_z_min : 8|8@1+ (1,0) [0|255] "" Vector__XXX
 SG_ rc_adcs_mtq_4_fsw_y_max : 0|8@1+ (1,0) [0|255] "" Vector__XXX
 SG_ rc_adcs_mtq_4_duty_z2_avg : 56|8@1+ (1,0) [0|255] "" Vector__XXX
 SG_ rc_adcs_mtq_4_duty_z1_avg : 48|8@1+ (1,0) [0|255] "" Vector__XXX
 SG_ rc_adcs_mtq_4_duty_y2_avg : 40|8@1+ (1,0) [0|255] "" Vector__XXX
 SG_ rc_adcs_mtq_4_duty_y1_avg : 32|8@1+ (1,0) [0|255] "" Vector__XXX
 SG_ rc_adcs_mtq_4_duty_x2_avg : 24|8@1+ (1,0) [0|255] "" Vector__XXX
 SG_ rc_adcs_mtq_4_duty_x1_avg : 16|8@1+ (1,0) [0|255] "" Vector__XXX

BO_ 2452161037 rc_adcs_mtq_3: 8 Vector__XXX
 SG_ rc_adcs_mtq_3_fsw_z_avg : 56|8@1+ (1,0) [0|255] "" Vector__XXX
 SG_ rc_adcs_mtq_3_fsw_y_min : 48|8@1+ (1,0) [0|255] "" Vector__XXX
 SG_ rc_adcs_mtq_3_fsw_y_max : 40|8@1+ (1,0) [0|255] "" Vector__XXX
 SG_ rc_adcs_mtq_3_fsw_y_avg : 32|8@1+ (1,0) [0|255] "" Vector__XXX
 SG_ rc_adcs_mtq_3_fsw_x_min : 24|8@1+ (1,0) [0|255] "" Vector__XXX
 SG_ rc_adcs_mtq_3_fsw_x_max : 16|8@1+ (1,0) [0|255] "" Vector__XXX
 SG_ rc_adcs_mtq_3_fsw_x_avg : 8|8@1+ (1,0) [0|255] "" Vector__XXX
 SG_ rc_adcs_mtq_3_bdot_z_min : 0|8@1+ (1,0) [0|255] "" Vector__XXX

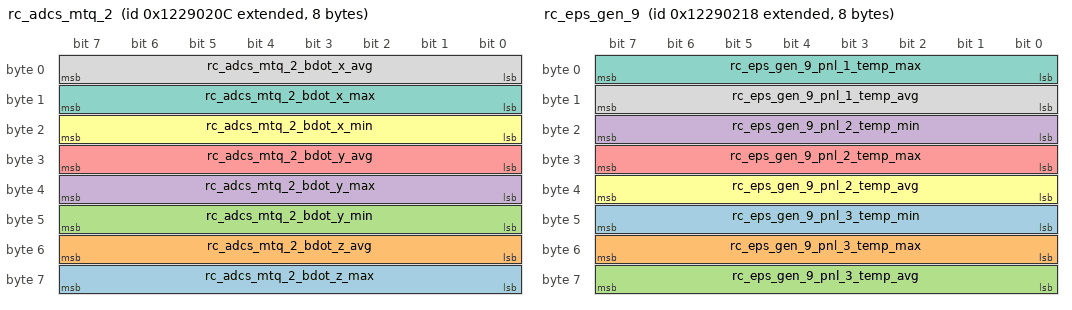
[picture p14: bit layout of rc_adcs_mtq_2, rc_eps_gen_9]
BO_ 2452161036 rc_adcs_mtq_2: 8 Vector__XXX
 SG_ rc_adcs_mtq_2_bdot_z_max : 56|8@1+ (1,0) [0|255] "" Vector__XXX
 SG_ rc_adcs_mtq_2_bdot_z_avg : 48|8@1+ (1,0) [0|255] "" Vector__XXX
 SG_ rc_adcs_mtq_2_bdot_y_min : 40|8@1+ (1,0) [0|255] "" Vector__XXX
 SG_ rc_adcs_mtq_2_bdot_y_max : 32|8@1+ (1,0) [0|255] "" Vector__XXX
 SG_ rc_adcs_mtq_2_bdot_y_avg : 24|8@1+ (1,0) [0|255] "" Vector__XXX
 SG_ rc_adcs_mtq_2_bdot_x_min : 16|8@1+ (1,0) [0|255] "" Vector__XXX
 SG_ rc_adcs_mtq_2_bdot_x_max : 8|8@1+ (1,0) [0|255] "" Vector__XXX
 SG_ rc_adcs_mtq_2_bdot_x_avg : 0|8@1+ (1,0) [0|255] "" Vector__XXX

BO_ 2452161035 rc_adcs_mtq_1: 8 Vector__XXX

BO_ 2452161034 rc_ppt_3: 6 Vector__XXX
 SG_ rc_ppt_3_ign_chg_min : 0|16@1+ (1,0) [-32768|32767] "2^-15 seconds" Vector__XXX
 SG_ rc_ppt_3_ign_chg_max : 16|16@1+ (1,0) [-32768|32767] "2^-15 seconds" Vector__XXX
 SG_ rc_ppt_3_ign_chg_avg : 32|16@1+ (1,0) [-32768|32767] "2^-15 seconds" Vector__XXX

BO_ 2452161033 rc_ppt_2: 8 Vector__XXX
 SG_ rc_ppt_2_total_fire_count : 48|16@1+ (1,0) [-32768|32767] "" Vector__XXX
 SG_ rc_ppt_2_main_chg_min : 0|16@1+ (1,0) [-32768|32767] "2^-15 seconds" Vector__XXX
 SG_ rc_ppt_2_main_chg_max : 16|16@1+ (1,0) [-32768|32767] "2^-15 seconds" Vector__XXX
 SG_ rc_ppt_2_main_chg_avg : 32|16@1+ (1,0) [-32768|32767] "2^-15 seconds" Vector__XXX

BO_ 2452161032 rc_ppt_1: 8 Vector__XXX

BO_ 2452161048 rc_eps_gen_9: 8 Vector__XXX
 SG_ rc_eps_gen_9_pnl_3_temp_min : 40|8@1- (1,0) [-128|127] "raw tmp36" Vector__XXX
 SG_ rc_eps_gen_9_pnl_3_temp_max : 48|8@1- (1,0) [-128|127] "raw tmp36" Vector__XXX
 SG_ rc_eps_gen_9_pnl_3_temp_avg : 56|8@1- (1,0) [-128|127] "raw tmp36" Vector__XXX
 SG_ rc_eps_gen_9_pnl_2_temp_min : 16|8@1- (1,0) [-128|127] "raw tmp36" Vector__XXX
 SG_ rc_eps_gen_9_pnl_2_temp_max : 24|8@1- (1,0) [-128|127] "raw tmp36" Vector__XXX
 SG_ rc_eps_gen_9_pnl_2_temp_avg : 32|8@1- (1,0) [-128|127] "raw tmp36" Vector__XXX
 SG_ rc_eps_gen_9_pnl_1_temp_max : 0|8@1- (1,0) [-128|127] "raw tmp36" Vector__XXX
 SG_ rc_eps_gen_9_pnl_1_temp_avg : 8|8@1- (1,0) [-128|127] "raw tmp36" Vector__XXX

BO_ 2452161047 rc_eps_gen_8: 7 Vector__XXX
 SG_ rc_eps_gen_8_pnl_3_power_min : 0|16@1- (1,0) [-32768|32767] "raw power gen" Vector__XXX
 SG_ rc_eps_gen_8_pnl_3_power_max : 16|16@1- (1,0) [-32768|32767] "raw power gen" Vector__XXX
 SG_ rc_eps_gen_8_pnl_3_power_avg : 32|16@1- (1,0) [-32768|32767] "raw power gen" Vector__XXX
 SG_ rc_eps_gen_8_pnl_1_temp_min : 48|8@1- (1,0) [-128|127] "raw tmp36" Vector__XXX

BO_ 2452161046 rc_eps_gen_7: 8 Vector__XXX
 SG_ rc_eps_gen_7_pnl_2_power_min : 16|16@1- (1,0) [-32768|32767] "raw power gen" Vector__XXX
 SG_ rc_eps_gen_7_pnl_2_power_max : 32|16@1- (1,0) [-32768|32767] "raw power gen" Vector__XXX
 SG_ rc_eps_gen_7_pnl_2_power_avg : 48|16@1- (1,0) [-32768|32767] "raw power gen" Vector__XXX
 SG_ rc_eps_gen_7_pnl_1_power_avg : 0|16@1- (1,0) [-32768|32767] "raw power gen" Vector__XXX

BO_ 2452161045 rc_eps_gen_6: 8 Vector__XXX
 SG_ rc_eps_gen_6_pnl_3_current_max : 0|16@1- (1,0) [-32768|32767] "raw node current gen" Vector__XXX
 SG_ rc_eps_gen_6_pnl_3_current_avg : 16|16@1- (1,0) [-32768|32767] "raw node current gen" Vector__XXX
 SG_ rc_eps_gen_6_pnl_1_power_min : 32|16@1- (1,0) [-32768|32767] "raw power gen" Vector__XXX
 SG_ rc_eps_gen_6_pnl_1_power_max : 48|16@1- (1,0) [-32768|32767] "raw power gen" Vector__XXX

BO_ 2452161044 rc_eps_gen_5: 8 Vector__XXX
 SG_ rc_eps_gen_5_pnl_3_current_min : 48|16@1- (1,0) [-32768|32767] "raw node current gen" Vector__XXX
 SG_ rc_eps_gen_5_pnl_2_current_min : 0|16@1- (1,0) [-32768|32767] "raw node current gen" Vector__XXX
 SG_ rc_eps_gen_5_pnl_2_current_max : 16|16@1- (1,0) [-32768|32767] "raw node current gen" Vector__XXX
 SG_ rc_eps_gen_5_pnl_2_current_avg : 32|16@1- (1,0) [-32768|32767] "raw node current gen" Vector__XXX

BO_ 2452161043 rc_eps_gen_4: 8 Vector__XXX
 SG_ rc_eps_gen_4_pnl_3_voltage_avg : 0|16@1+ (1,0) [0|20000] "raw node voltage" Vector__XXX
 SG_ rc_eps_gen_4_pnl_1_current_min : 16|16@1- (1,0) [-32768|32767] "raw node current gen" Vector__XXX
 SG_ rc_eps_gen_4_pnl_1_current_max : 32|16@1- (1,0) [-32768|32767] "raw node current gen" Vector__XXX
 SG_ rc_eps_gen_4_pnl_1_current_avg : 48|16@1- (1,0) [-32768|32767] "raw node current gen" Vector__XXX

BO_ 2452161042 rc_eps_gen_3: 8 Vector__XXX
 SG_ rc_eps_gen_3_pnl_3_voltage_min : 32|16@1+ (1,0) [0|20000] "raw node voltage" Vector__XXX
 SG_ rc_eps_gen_3_pnl_3_voltage_max : 48|16@1+ (1,0) [0|20000] "raw node voltage" Vector__XXX
 SG_ rc_eps_gen_3_pnl_2_voltage_max : 0|16@1+ (1,0) [0|20000] "raw node voltage" Vector__XXX
 SG_ rc_eps_gen_3_pnl_2_voltage_avg : 16|16@1+ (1,0) [0|20000] "raw node voltage" Vector__XXX

BO_ 2452161041 rc_eps_gen_2: 8 Vector__XXX
 SG_ rc_eps_gen_2_pnl_2_voltage_min : 48|16@1+ (1,0) [0|20000] "raw node voltage" Vector__XXX
 SG_ rc_eps_gen_2_pnl_1_voltage_min : 0|16@1+ (1,0) [0|20000] "raw node voltage" Vector__XXX
 SG_ rc_eps_gen_2_pnl_1_voltage_max : 16|16@1+ (1,0) [0|20000] "raw node voltage" Vector__XXX
 SG_ rc_eps_gen_2_pnl_1_voltage_avg : 32|16@1+ (1,0) [0|20000] "raw node voltage" Vector__XXX

BO_ 2452161040 rc_eps_gen_1: 8 Vector__XXX

BO_ 2452161029 rc_eps_batt_6: 7 Vector__XXX
 SG_ rc_eps_batt_6_status : 0|8@1+ (1,0) [0|255] "" Vector__XXX
 SG_ rc_eps_batt_6_ctrl : 8|8@1+ (1,0) [0|255] "" Vector__XXX
 SG_ rc_eps_batt_6_last_charge : 16|40@1+ (1,0) [0|1099511627775] "2^-8 seconds" Vector__XXX

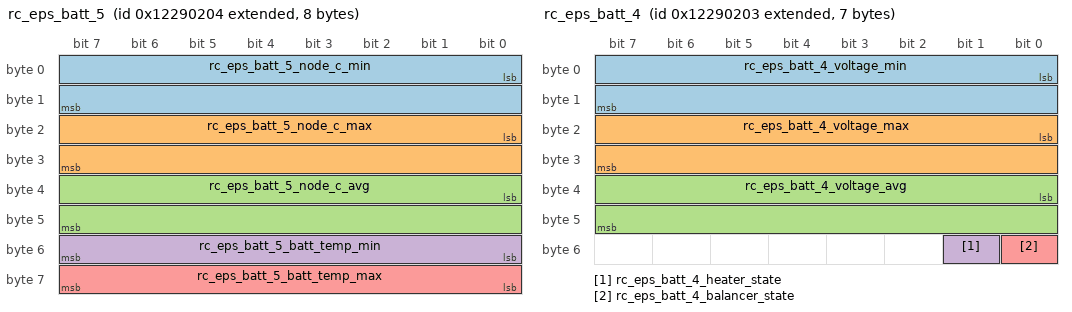
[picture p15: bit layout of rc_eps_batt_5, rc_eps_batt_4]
BO_ 2452161028 rc_eps_batt_5: 8 Vector__XXX
 SG_ rc_eps_batt_5_node_c_min : 0|16@1- (1,0) [-32768|32767] "raw node current batt" Vector__XXX
 SG_ rc_eps_batt_5_node_c_max : 16|16@1- (1,0) [-32768|32767] "raw node current batt" Vector__XXX
 SG_ rc_eps_batt_5_node_c_avg : 32|16@1- (1,0) [-32768|32767] "raw node current batt" Vector__XXX
 SG_ rc_eps_batt_5_batt_temp_min : 48|8@1- (1,0) [-128|127] "raw tmp36" Vector__XXX
 SG_ rc_eps_batt_5_batt_temp_max : 56|8@1- (1,0) [-128|127] "raw tmp36" Vector__XXX

BO_ 2452161027 rc_eps_batt_4: 7 eps_batt
 SG_ rc_eps_batt_4_voltage_min : 0|16@1+ (1,0) [0|65535] "raw voltage" Vector__XXX
 SG_ rc_eps_batt_4_voltage_max : 16|16@1+ (1,0) [0|65535] "raw voltage" Vector__XXX
 SG_ rc_eps_batt_4_voltage_avg : 32|16@1+ (1,0) [0|65535] "raw voltage" Vector__XXX
 SG_ rc_eps_batt_4_heater_state : 49|1@1+ (1,0) [0|1] "" Vector__XXX
 SG_ rc_eps_batt_4_balancer_state : 48|1@1+ (1,0) [0|1] "" Vector__XXX

BO_ 2452161026 rc_eps_batt_3: 7 eps_batt
 SG_ rc_eps_batt_3_current_min : 0|16@1+ (1,0) [0|65535] "raw current batt" Vector__XXX
 SG_ rc_eps_batt_3_current_max : 16|16@1+ (1,0) [0|65535] "raw current batt" Vector__XXX
 SG_ rc_eps_batt_3_current_avg : 32|16@1+ (1,0) [0|65535] "raw current batt" Vector__XXX
 SG_ rc_eps_batt_3_batt_temp_avg : 48|8@1- (1,0) [-128|127] "raw tmp36" Vector__XXX

BO_ 2452161025 rc_eps_batt_2: 6 eps_batt
 SG_ rc_eps_batt_2_node_v_min : 0|16@1+ (1,0) [0|65535] "raw node voltage" Vector__XXX
 SG_ rc_eps_batt_2_node_v_max : 16|16@1+ (1,0) [0|65535] "raw node voltage" Vector__XXX
 SG_ rc_eps_batt_2_node_v_avg : 32|16@1+ (1,0) [0|65535] "raw node voltage" Vector__XXX

BO_ 2452161024 rc_eps_batt_1: 8 eps_batt

BO_ 2449735942 cmd_ppt_set_count: 1 Vector__XXX
 SG_ cmd_ppt_set_count_count : 0|8@1+ (1,0) [0|30] "" Vector__XXX

BO_ 2449735941 cmd_ppt_time_upd: 8 Vector__XXX
 SG_ cmd_ppt_time_upd_ign_charge : 32|16@1+ (1,0) [0|65535] "2^-15s" Vector__XXX
 SG_ cmd_ppt_time_upd_cooldown : 48|16@1+ (1,0) [0|65535] "2^-15s" Vector__XXX
 SG_ cmd_ppt_time_upd_ign_delay : 16|16@1+ (1,0) [0|65535] "2^-15s" Vector__XXX
 SG_ cmd_ppt_time_upd_charge : 0|16@1+ (1,0) [0|65535] "2^-15s" Vector__XXX

BO_ 2432958724 cmd_ppt_halt: 1 Vector__XXX
 SG_ cmd_ppt_halt_confirm : 0|1@1+ (1,0) [0|1] "" Vector__XXX

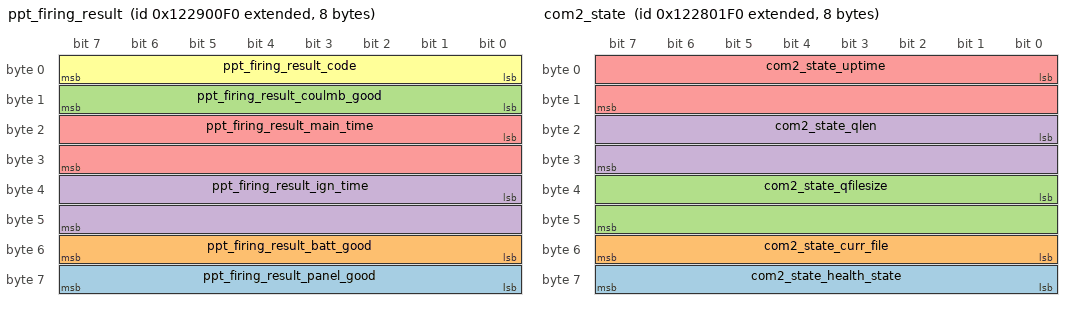
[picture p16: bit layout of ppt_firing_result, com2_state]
BO_ 2452160752 ppt_firing_result: 8 Vector__XXX
 SG_ ppt_firing_result_panel_good : 56|8@1+ (1,0) [0|2] "" Vector__XXX
 SG_ ppt_firing_result_batt_good : 48|8@1- (1,0) [0|2] "" Vector__XXX
 SG_ ppt_firing_result_coulmb_good : 8|8@1+ (1,0) [0|2] "" Vector__XXX
 SG_ ppt_firing_result_ign_time : 32|16@1+ (1,0) [0|65535] "2^-15s" Vector__XXX
 SG_ ppt_firing_result_main_time : 16|16@1+ (1,0) [0|65535] "2^-15s" Vector__XXX
 SG_ ppt_firing_result_code : 0|8@1+ (1,0) [0|3] "" Vector__XXX

BO_ 2457272392 tle_5: 8 com_1
 SG_ tle_5_mnm : 0|64@1- (1,0) [-1.7E+308|1.7E+308] "" Vector__XXX

BO_ 2457272391 tle_4: 8 com_1
 SG_ tle_4_aop : 32|32@1- (1,0) [-3.4E+038|3.4E+038] "" Vector__XXX
 SG_ tle_4_raan : 0|32@1- (1,0) [-3.4E+038|3.4E+038] "" Vector__XXX

BO_ 2457272390 tle_3: 8 com_1
 SG_ tle_3_ecc : 32|32@1- (1,0) [-3.4E+038|3.4E+038] "" Vector__XXX
 SG_ tle_3_inc : 0|32@1- (1,0) [-3.4E+038|3.4E+038] "" Vector__XXX

BO_ 2457272389 tle_2: 8 com_1
 SG_ tle_2_day : 0|64@1- (1,0) [-1.7E+308|1.7E+308] "" Vector__XXX

BO_ 2449932356 tle_1: 8 com_1
 SG_ tle_1_mna : 32|32@1- (1,0) [-3.4E+038|3.4E+038] "" Vector__XXX
 SG_ tle_1_bstar : 0|32@1- (1,0) [-3.4E+038|3.4E+038] "" Vector__XXX

BO_ 2451701986 eps_pd_undervoltage: 1 Vector__XXX
 SG_ eps_pd_undervoltage_state : 0|1@1+ (1,0) [0|1] "" Vector__XXX

BO_ 2451701985 eps_pd_batt_voltage: 3 Vector__XXX
 SG_ eps_pd_batt_voltage_agg : 16|8@1+ (1,0) [0|5] "" Vector__XXX
 SG_ eps_pd_batt_voltage_val : 0|16@1+ (1,0) [0|10000] "mV" Vector__XXX

BO_ 2451702033 cmd_pd_rst: 1 Vector__XXX
 SG_ cmd_pd_rst_confirm : 0|1@1+ (1,0) [0|1] "" Vector__XXX

BO_ 2449998321 cmd_com2_run: 2 Vector__XXX
 SG_ cmd_com2_run_clear : 9|1@1+ (1,0) [0|1] "" Vector__XXX
 SG_ cmd_com2_run_jump : 8|1@1+ (1,0) [0|1] "" Vector__XXX
 SG_ cmd_com2_run_fileno : 0|8@1+ (1,0) [0|255] "" Vector__XXX

BO_ 2452095472 com2_state: 8 com_2
 SG_ com2_state_health_state : 56|8@1+ (1,0) [0|255] "" Vector__XXX
 SG_ com2_state_curr_file : 48|8@1+ (1,0) [0|255] "" Vector__XXX
 SG_ com2_state_qfilesize : 32|16@1+ (1,0) [0|65535] "kB" Vector__XXX
 SG_ com2_state_qlen : 16|16@1+ (1,0) [0|65535] "files" Vector__XXX
 SG_ com2_state_uptime : 0|16@1+ (1,0) [0|65535] "s" Vector__XXX

BO_ 2450784513 cmd_pd_enable: 2 Vector__XXX
 SG_ cmd_pd_enable_enable : 8|1@1+ (1,0) [0|1] "" Vector__XXX
 SG_ cmd_pd_enable_domain : 0|8@1+ (1,0) [0|8] "" Vector__XXX

BO_ 2451833090 cmd_batt_rst: 1 Vector__XXX
 SG_ cmd_batt_rst_confirm : 0|1@1+ (1,0) [0|1] "" Vector__XXX

BO_ 2451833091 cmd_batt_bal_enable: 1 Vector__XXX
 SG_ cmd_batt_bal_enable_enable : 0|1@1+ (1,0) [0|1] "" Vector__XXX

BO_ 2148794376 cmd_reboot_request: 1 rahs
 SG_ cmd_reboot_request_domain : 0|8@1+ (1,0) [0|8] "" Vector__XXX

BO_ 2451832868 cmd_ignore_fsw: 1 Vector__XXX
 SG_ cmd_ignore_fsw_ignore : 0|1@1+ (1,0) [0|1] "" Vector__XXX

BO_ 2451832867 cmd_mtq_fsw: 4 adcs_estim
 SG_ cmd_mtq_fsw_sc_mode : 24|8@1+ (1,0) [0|3] "" Vector__XXX
 SG_ cmd_mtq_fsw_z : 16|8@1- (1,0) [-100|100] "pct doodie" Vector__XXX
 SG_ cmd_mtq_fsw_y : 8|8@1- (1,0) [-100|100] "pct doodie" Vector__XXX
 SG_ cmd_mtq_fsw_x : 0|8@1- (1,0) [-100|100] "pct doodie" Vector__XXX

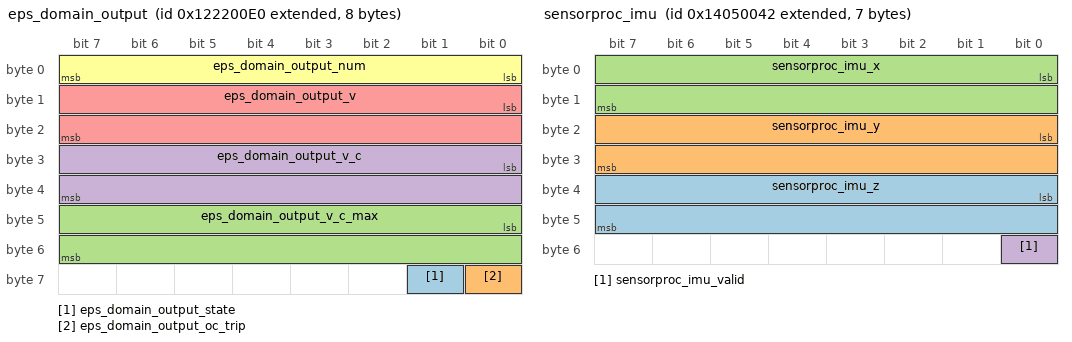
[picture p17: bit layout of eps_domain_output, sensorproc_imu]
BO_ 2451701984 eps_domain_output: 8 eps_dist
 SG_ eps_domain_output_state : 57|1@1+ (1,0) [0|1] "" Vector__XXX
 SG_ eps_domain_output_oc_trip : 56|1@1+ (1,0) [0|1] "" Vector__XXX
 SG_ eps_domain_output_v_c_max : 40|16@1+ (1,0) [0|3200] "mA" Vector__XXX
 SG_ eps_domain_output_v_c : 24|16@1+ (1,0) [0|3200] "mA" Vector__XXX
 SG_ eps_domain_output_v : 8|16@1+ (1,0) [0|10000] "mV" Vector__XXX
 SG_ eps_domain_output_num : 0|8@1+ (1,0) [0|8] "" Vector__XXX

BO_ 2483355714 sensorproc_imu: 7 adcs_sensorproc
 SG_ sensorproc_imu_z : 32|16@1- (1,0) [-32768|32767] "0.004375 deg/s" Vector__XXX
 SG_ sensorproc_imu_y : 16|16@1- (1,0) [-32768|32767] "0.004375 deg/s" Vector__XXX
 SG_ sensorproc_imu_x : 0|16@1- (1,0) [-32768|32767] "0.004375 deg/s" Vector__XXX
 SG_ sensorproc_imu_valid : 48|1@1+ (1,0) [0|1] "bool" Vector__XXX

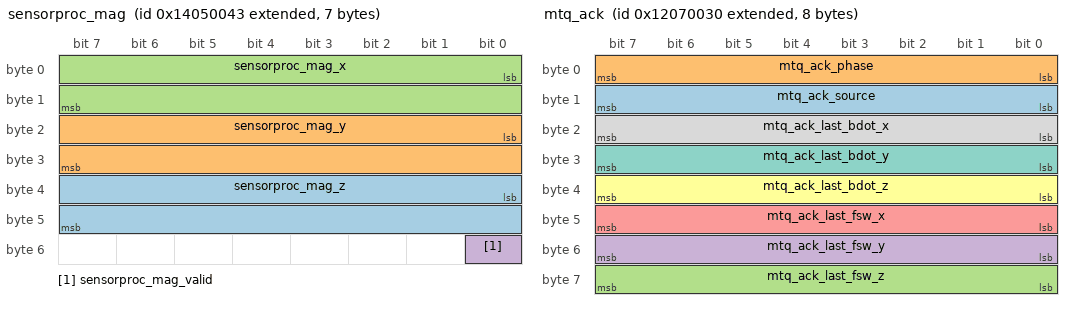
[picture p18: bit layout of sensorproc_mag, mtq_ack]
BO_ 2483355715 sensorproc_mag: 7 adcs_sensorproc
 SG_ sensorproc_mag_z : 32|16@1- (1,0) [-32768|32767] "73 nanoTeslas" Vector__XXX
 SG_ sensorproc_mag_y : 16|16@1- (1,0) [-32768|32767] "73 nanoTeslas" Vector__XXX
 SG_ sensorproc_mag_x : 0|16@1- (1,0) [-32768|32767] "73 nanoTeslas" Vector__XXX
 SG_ sensorproc_mag_valid : 48|1@1+ (1,0) [0|1] "bool" Vector__XXX

BO_ 2148597780 cmd_rollcall: 7 eps_dist
 SG_ cmd_rollcall_type : 48|8@1+ (1,0) [0|255] "" Vector__XXX
 SG_ cmd_rollcall_met_overflow : 40|8@1+ (1,0) [0|255] "" Vector__XXX
 SG_ cmd_rollcall_met : 8|32@1+ (1,0) [0|4294967295] "2^-8 s" Vector__XXX
 SG_ cmd_rollcall_msp : 0|8@1+ (1,0) [0|255] "" Vector__XXX

BO_ 2449932336 mtq_ack: 8 adcs_mtq
 SG_ mtq_ack_source : 8|8@1- (1,0) [-128|1] "" Vector__XXX
 SG_ mtq_ack_phase : 0|8@1- (1,0) [-128|3] "" Vector__XXX
 SG_ mtq_ack_last_fsw_z : 56|8@1- (1,0) [-128|100] "pct" Vector__XXX
 SG_ mtq_ack_last_fsw_y : 48|8@1- (1,0) [-128|100] "pct" Vector__XXX
 SG_ mtq_ack_last_fsw_x : 40|8@1- (1,0) [-128|100] "pct" Vector__XXX
 SG_ mtq_ack_last_bdot_z : 32|8@1- (1,0) [-128|100] "pct" Vector__XXX
 SG_ mtq_ack_last_bdot_y : 24|8@1- (1,0) [-128|100] "pct" Vector__XXX
 SG_ mtq_ack_last_bdot_x : 16|8@1- (1,0) [-128|100] "pct" Vector__XXX

BO_ 2452160723 gen_panel_temp: 4 eps_gen
 SG_ gen_panel_temp_agg : 24|8@1+ (1,0) [0|5] "" Vector__XXX
 SG_ gen_panel_temp_x_pos : 16|8@1- (1,0) [-128|127] "" Vector__XXX
 SG_ gen_panel_temp_y_neg : 8|8@1- (1,0) [-128|127] "" Vector__XXX
 SG_ gen_panel_temp_y_pos : 0|8@1- (1,0) [-128|127] "" Vector__XXX

BO_ 2450784528 cmd_gen_rst: 1 eps_gen
 SG_ cmd_gen_rst_confirm : 0|1@1+ (1,0) [0|1] "bool" Vector__XXX

BO_ 2450784512 cmd_ppt_single_fire: 1 com_1
 SG_ cmd_ppt_single_fire_override : 1|1@1+ (1,0) [0|1] "" Vector__XXX
 SG_ cmd_ppt_single_fire_with_pulse : 0|1@1+ (1,0) [0|1] "" Vector__XXX

BO_ 2451701970 gen_panel_pwr: 7 eps_gen
 SG_ gen_panel_pwr_agg : 48|8@1- (1,0) [0|5] "" Vector__XXX
 SG_ gen_panel_pwr_x_pos : 32|16@1+ (1,0) [0|20000] "mW" Vector__XXX
 SG_ gen_panel_pwr_y_neg : 16|16@1+ (1,0) [0|20000] "mW" Vector__XXX
 SG_ gen_panel_pwr_y_pos : 0|16@1+ (1,0) [0|20000] "mW" Vector__XXX

BO_ 2451701969 gen_panel_current: 6 eps_gen
 SG_ gen_panel_current_x_pos : 32|16@1+ (1,0) [0|1000] "mA" Vector__XXX
 SG_ gen_panel_current_y_neg : 16|16@1+ (1,0) [0|1000] "mA" Vector__XXX
 SG_ gen_panel_current_y_pos : 0|16@1+ (1,0) [0|1000] "mA" Vector__XXX

BO_ 2450653392 gen_panel_voltage: 6 eps_gen
 SG_ gen_panel_voltage_x_pos : 32|16@1+ (1,0) [0|20000] "mV" Vector__XXX
 SG_ gen_panel_voltage_y_neg : 16|16@1+ (1,0) [0|20000] "mV" Vector__XXX
 SG_ gen_panel_voltage_y_pos : 0|16@1+ (1,0) [0|20000] "mV" Vector__XXX

BO_ 2453078050 mpc_vp: 1 adcs_mpc
 SG_ mpc_vp_status : 0|1@1+ (1,0) [0|1] "" Vector__XXX

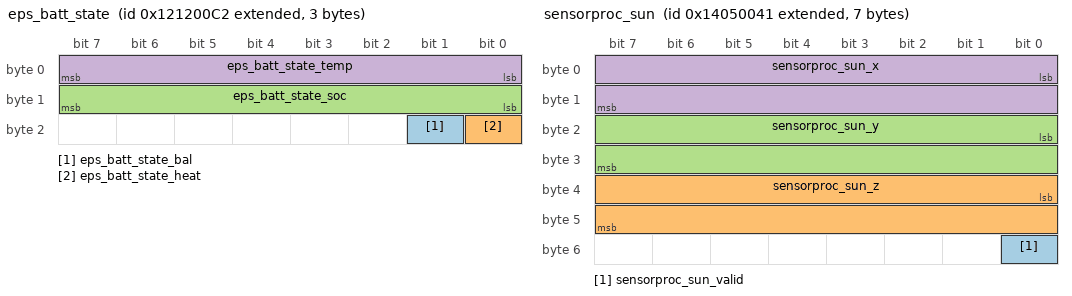
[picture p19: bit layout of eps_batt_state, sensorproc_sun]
BO_ 2450653378 eps_batt_state: 3 eps_batt
 SG_ eps_batt_state_bal : 17|1@1+ (1,0) [0|1] "" Vector__XXX
 SG_ eps_batt_state_heat : 16|1@1+ (1,0) [0|1] "" Vector__XXX
 SG_ eps_batt_state_soc : 8|8@1+ (1,0) [0|100] "pct" Vector__XXX
 SG_ eps_batt_state_temp : 0|8@1- (1,0) [-128|127] "Deg C" Vector__XXX

BO_ 2450653377 eps_batt_current: 8 eps_batt
 SG_ eps_batt_current_node_c : 48|16@1- (1,0) [-1000|1000] "dmA (0.1mA)" Vector__XXX
 SG_ eps_batt_current_min_c : 32|16@1- (1,0) [-700|1200] "cA" Vector__XXX
 SG_ eps_batt_current_max_c : 16|16@1- (1,0) [-700|1200] "cA" Vector__XXX
 SG_ eps_batt_current_c : 0|16@1- (1,0) [-700|1200] "cA" Vector__XXX

BO_ 2450653376 eps_batt_voltage: 8 eps_batt
 SG_ eps_batt_voltage_v_max_delta : 48|16@1+ (1,0) [0|10000] "mV" Vector__XXX
 SG_ eps_batt_voltage_node_v : 32|16@1+ (1,0) [0|10000] "mV" Vector__XXX
 SG_ eps_batt_voltage_min_v : 16|16@1+ (1,0) [0|10000] "mV" Vector__XXX
 SG_ eps_batt_voltage_v : 0|16@1+ (1,0) [0|10000] "mV" Vector__XXX

BO_ 2483355713 sensorproc_sun: 7 adcs_sensorproc
 SG_ sensorproc_sun_valid : 48|1@1+ (1,0) [0|1] "bool" Vector__XXX
 SG_ sensorproc_sun_z : 32|16@1- (1,0) [-32768|32767] "" Vector__XXX
 SG_ sensorproc_sun_y : 16|16@1- (1,0) [-32768|32767] "" Vector__XXX
 SG_ sensorproc_sun_x : 0|16@1- (1,0) [-32768|32767] "" Vector__XXX

BO_ 2452029473 cmd_mtq_bdot: 3 adcs_bdot
 SG_ cmd_mtq_bdot_z : 16|8@1- (1,0) [-100|100] "pct doodie" Vector__XXX
 SG_ cmd_mtq_bdot_y : 8|8@1- (1,0) [-100|100] "pct doodie" Vector__XXX
 SG_ cmd_mtq_bdot_x : 0|8@1- (1,0) [-100|100] "pct doodie" Vector__XXX

BO_ 2449932320 bdot_tumble_status: 1 adcs_bdot
 SG_ bdot_tumble_status_status : 0|1@1+ (1,0) [0|1] "bool" Vector__XXX

BO_ 2147549202 sync_2: 0 eps_gen

BO_ 2147549201 sync_1: 0 ppt

BO_ 2452160531 msp_temp: 2 rahs
 SG_ msp_temp_temp : 0|16@1- (1,0) [-32768|32767] "cC" Vector__XXX

BO_ 2449932985 grnd_epoch: 5 Vector__XXX
 SG_ grnd_epoch_val_overflow : 32|8@1+ (1,0) [0|255] "" Vector__XXX
 SG_ grnd_epoch_val : 0|32@1+ (1,0) [0|4294967295] "2^-8 s" Vector__XXX

BO_TX_BU_ 2148794376 : adcs_bdot,adcs_estim,adcs_mpc,adcs_mtq,adcs_rwx,adcs_rwy,adcs_rwz,adcs_sensorproc,com_1,com_2,eps_batt,eps_dist,eps_gen,ppt,rahs;
BO_TX_BU_ 2452160531 : eps_batt,adcs_bdot,adcs_estim,adcs_mpc,adcs_mtq,adcs_rwx,adcs_rwy,adcs_rwz,adcs_sensorproc,com_1,com_2,eps_dist,eps_gen,ppt,rahs;

CM_ BO_ 2452161087 "deprecated";
CM_ BO_ 2452161088 "deprecated";
CM_ BO_ 2452161089 "deprecated";
BA_DEF_  "BusType" STRING ;
BA_DEF_DEF_  "BusType" "CAN";
VAL_ 2449736397 gcmd_mtq_pms_enable 2 "null" 1 "true" 0 "false" ;
VAL_ 2449736395 gcmd_bdot_spam_control 2 "null" 1 "true" 0 "false" ;
VAL_ 2449736394 gcmd_bdot_control_mode 3 "spam" 2 "spam mag self test" 1 "sleep mode" 0 "normal mode" ;
VAL_ 2449736393 gcmd_bdot_mag_control_mode 3 "sp2 mode" 2 "sp1 mode" 1 "bdot mode" 0 "auto mode" ;
VAL_ 2449736392 gcmd_bdot_pole_override_z 2 "null" 1 "true" 0 "false" ;
VAL_ 2449736392 gcmd_bdot_pole_override_y 2 "null" 1 "true" 0 "false" ;
VAL_ 2449736392 gcmd_bdot_pole_override_x 2 "null" 1 "true" 0 "false" ;
VAL_ 2449736390 gcmd_gen_set_pt_state_3 2 "null" 1 "true" 0 "false" ;
VAL_ 2449736390 gcmd_gen_set_pt_state_2 2 "null" 1 "true" 0 "false" ;
VAL_ 2449736390 gcmd_gen_set_pt_state_1 2 "null" 1 "true" 0 "false" ;
VAL_ 2449736381 gcmd_dist_set_pd_state_wheels 2 "null" 1 "true" 0 "false" ;
VAL_ 2449736381 gcmd_dist_set_pd_state_rahs 2 "null" 1 "true" 0 "false" ;
VAL_ 2449736381 gcmd_dist_set_pd_state_ppt 2 "null" 1 "true" 0 "false" ;
VAL_ 2449736381 gcmd_dist_set_pd_state_estim 2 "null" 1 "true" 0 "false" ;
VAL_ 2449736381 gcmd_dist_set_pd_state_eps 2 "null" 1 "true" 0 "false" ;
VAL_ 2449736381 gcmd_dist_set_pd_state_com2 2 "null" 1 "true" 0 "false" ;
VAL_ 2449736381 gcmd_dist_set_pd_state_com1 2 "null" 1 "true" 0 "false" ;
VAL_ 2449736381 gcmd_dist_set_pd_state_bdot 2 "null" 1 "true" 0 "false" ;
VAL_ 2449932988 gcmd_mtq_pop_z 2 "null" 1 "true" 0 "false" ;
VAL_ 2449932988 gcmd_mtq_pop_y 2 "null" 1 "true" 0 "false" ;
VAL_ 2449932988 gcmd_mtq_pop_x 2 "null" 1 "true" 0 "false" ;
VAL_ 2483355716 sensorproc_mag2_valid 1 "true" 0 "false" ;
VAL_ 2452161106 rc_eps_dist_16_ppt_state 3 "off_batt_undervoltage" 2 "off_overcurrent" 1 "off_manual" 0 "on" ;
VAL_ 2452161096 rc_eps_dist_6_com2_state 3 "off_batt_undervoltage" 2 "off_overcurrent" 1 "off_manual" 0 "on" ;
VAL_ 2452161092 rc_eps_dist_2_uv_state 1 "undervoltage" 0 "normal" ;
VAL_ 2452161104 rc_eps_dist_14_eps_state 3 "off_batt_undervoltage" 2 "off_overcurrent" 1 "off_manual" 0 "on" ;
VAL_ 2452161102 rc_eps_dist_12_estim_state 3 "off_batt_undervoltage" 2 "off_overcurrent" 1 "off_manual" 0 "on" ;
VAL_ 2452161100 rc_eps_dist_10_bdot_state 3 "off_batt_undervoltage" 2 "off_overcurrent" 1 "off_manual" 0 "on" ;
VAL_ 2452161098 rc_eps_dist_8_rahs_state 3 "off_batt_undervoltage" 2 "off_overcurrent" 1 "off_manual" 0 "on" ;
VAL_ 2452161094 rc_eps_dist_4_com1_state 3 "off_batt_undervoltage" 2 "off_overcurrent" 1 "off_manual" 0 "on" ;
VAL_ 2452161075 rc_adcs_estim_8_tle_id 1 "true" 0 "false" ;
VAL_ 2452161075 rc_adcs_estim_8_sc_in_sun 1 "true" 0 "false" ;
VAL_ 2452161075 rc_adcs_estim_8_sc_above_gs 1 "true" 0 "false" ;
VAL_ 2452161050 rc_adcs_bdot_4_tumble 1 "true" 0 "false" ;
VAL_ 2449932984 estim_state_in_sun 1 "true" 0 "false" ;
VAL_ 2449932984 estim_state_above_gs 1 "true" 0 "false" ;
VAL_ 2452161027 rc_eps_batt_4_heater_state 1 "true" 0 "false" ;
VAL_ 2452161027 rc_eps_batt_4_balancer_state 1 "true" 0 "false" ;
VAL_ 2432958724 cmd_ppt_halt_confirm 1 "true" 0 "false" ;
VAL_ 2452160752 ppt_firing_result_panel_good 2 "null" 1 "true" 0 "false" ;
VAL_ 2452160752 ppt_firing_result_batt_good 2 "null" 1 "true" 0 "false" ;
VAL_ 2452160752 ppt_firing_result_coulmb_good 2 "null" 1 "true" 0 "false" ;
VAL_ 2452160752 ppt_firing_result_code 3 "no discharge" 2 "no charge" 1 "fire overridden" 0 "fire successful" ;
VAL_ 2451701986 eps_pd_undervoltage_state 1 "undervoltage" 0 "normal" ;
VAL_ 2451701985 eps_pd_batt_voltage_agg 5 "sum" 4 "max" 3 "min" 2 "count" 1 "avg" 0 "none" ;
VAL_ 2449998321 cmd_com2_run_clear 1 "true" 0 "false" ;
VAL_ 2449998321 cmd_com2_run_jump 1 "true" 0 "false" ;
VAL_ 2450784513 cmd_pd_enable_enable 1 "true" 0 "false" ;
VAL_ 2450784513 cmd_pd_enable_domain 8 "unk" 7 "com1" 6 "com2" 5 "rahs" 4 "bdot" 3 "estim" 2 "wheel" 1 "eps" 0 "ppt" ;
VAL_ 2451833090 cmd_batt_rst_confirm 1 "true" 0 "false" ;
VAL_ 2451833091 cmd_batt_bal_enable_enable 1 "true" 0 "false" ;
VAL_ 2148794376 cmd_reboot_request_domain 8 "unk" 7 "com1" 6 "com2" 5 "rahs" 4 "bdot" 3 "estim" 2 "wheel" 1 "eps" 0 "ppt" ;
VAL_ 2451832868 cmd_ignore_fsw_ignore 1 "true" 0 "false" ;
VAL_ 2451832867 cmd_mtq_fsw_sc_mode 3 "not tumbling charlie" 2 "not tumbling bob" 1 "not tumbling alice" 0 "tumbling" ;
VAL_ 2451701984 eps_domain_output_state 1 "true" 0 "false" ;
VAL_ 2451701984 eps_domain_output_oc_trip 1 "true" 0 "false" ;
VAL_ 2451701984 eps_domain_output_num 8 "unk" 7 "com1" 6 "com2" 5 "rahs" 4 "bdot" 3 "estim" 2 "wheel" 1 "eps" 0 "ppt" ;
VAL_ 2483355714 sensorproc_imu_valid 1 "true" 0 "false" ;
VAL_ 2483355715 sensorproc_mag_valid 1 "true" 0 "false" ;
VAL_ 2449932336 mtq_ack_phase 2 "pms_phase" 1 "actuation_phase" 0 "measurement_phase" ;
VAL_ 2452160723 gen_panel_temp_agg 5 "sum" 4 "max" 3 "min" 2 "count" 1 "avg" 0 "none" ;
VAL_ 2450784528 cmd_gen_rst_confirm 1 "true" 0 "false" ;
VAL_ 2450784512 cmd_ppt_single_fire_override 1 "true" 0 "false" ;
VAL_ 2450784512 cmd_ppt_single_fire_with_pulse 1 "true" 0 "false" ;
VAL_ 2451701970 gen_panel_pwr_agg 5 "sum" 4 "max" 3 "min" 2 "count" 1 "avg" 0 "none" ;
VAL_ 2453078050 mpc_vp_status 1 "true" 0 "false" ;
VAL_ 2450653378 eps_batt_state_bal 1 "true" 0 "false" ;
VAL_ 2450653378 eps_batt_state_heat 1 "true" 0 "false" ;
VAL_ 2483355713 sensorproc_sun_valid 1 "true" 0 "false" ;
VAL_ 2449932320 bdot_tumble_status_status 1 "true" 0 "false" ;
SIG_VALTYPE_ 2449736399 gcmd_eps_batt_fulldef_const_volt : 1;
SIG_VALTYPE_ 2449736399 gcmd_eps_batt_fulldef_chg_curr : 1;
SIG_VALTYPE_ 2449736389 gcmd_dist_set_pd_ovc_ppt_ovc : 1;
SIG_VALTYPE_ 2449736388 gcmd_dist_set_pd_ovc_eps_ovc : 1;
SIG_VALTYPE_ 2449736387 gcmd_dist_set_pd_ovc_wheels_ovc : 1;
SIG_VALTYPE_ 2449736386 gcmd_dist_set_pd_ovc_estim_ovc : 1;
SIG_VALTYPE_ 2449736385 gcmd_dist_set_pd_ovc_bdot_ovc : 1;
SIG_VALTYPE_ 2449736384 gcmd_dist_set_pd_ovc_rahs_ovc : 1;
SIG_VALTYPE_ 2449736383 gcmd_dist_set_pd_ovc_com2_ovc : 1;
SIG_VALTYPE_ 2449736382 gcmd_dist_set_pd_ovc_com1_ovc : 1;
SIG_VALTYPE_ 2452161113 rc_adcs_estim_14_mag_z : 2;
SIG_VALTYPE_ 2452161112 rc_adcs_estim_13_mag_y : 2;
SIG_VALTYPE_ 2452161111 rc_adcs_estim_12_mag_x : 2;
SIG_VALTYPE_ 2452161110 rc_adcs_estim_11_sun_z : 2;
SIG_VALTYPE_ 2452161109 rc_adcs_estim_10_sun_y : 2;
SIG_VALTYPE_ 2452161108 rc_adcs_estim_9_sun_x : 2;
SIG_VALTYPE_ 2452161086 rc_adcs_mpc_11_omega_z : 2;
SIG_VALTYPE_ 2452161082 rc_adcs_mpc_7_omega_max : 2;
SIG_VALTYPE_ 2452161083 rc_adcs_mpc_8_omega_avg : 2;
SIG_VALTYPE_ 2452161084 rc_adcs_mpc_9_omega_x : 2;
SIG_VALTYPE_ 2452161080 rc_adcs_mpc_5_sc_quat_4 : 2;
SIG_VALTYPE_ 2452161081 rc_adcs_mpc_6_omega_min : 2;
SIG_VALTYPE_ 2452161079 rc_adcs_mpc_4_sc_quat_3 : 2;
SIG_VALTYPE_ 2452161078 rc_adcs_mpc_3_sc_quat_2 : 2;
SIG_VALTYPE_ 2452161085 rc_adcs_mpc_10_omega_y : 2;
SIG_VALTYPE_ 2452161077 rc_adcs_mpc_2_sc_quat_1 : 2;
SIG_VALTYPE_ 2452161074 rc_adcs_estim_7_vel_z : 2;
SIG_VALTYPE_ 2452161073 rc_adcs_estim_6_vel_y : 2;
SIG_VALTYPE_ 2452161072 rc_adcs_estim_5_vel_x : 2;
SIG_VALTYPE_ 2452161071 rc_adcs_estim_4_pos_z : 2;
SIG_VALTYPE_ 2452161069 rc_adcs_estim_2_pos_x : 2;
SIG_VALTYPE_ 2452161070 rc_adcs_estim_3_pos_y : 2;
SIG_VALTYPE_ 2449932980 estim_sun_unit_z_val : 2;
SIG_VALTYPE_ 2449932979 estim_sun_unit_y_val : 2;
SIG_VALTYPE_ 2449932978 estim_sun_unit_x_val : 2;
SIG_VALTYPE_ 2449932983 estim_mag_unit_z_val : 2;
SIG_VALTYPE_ 2449932982 estim_mag_unit_y_val : 2;
SIG_VALTYPE_ 2449932981 estim_mag_unit_x_val : 2;
SIG_VALTYPE_ 2457272392 tle_5_mnm : 2;
SIG_VALTYPE_ 2457272391 tle_4_aop : 1;
SIG_VALTYPE_ 2457272391 tle_4_raan : 1;
SIG_VALTYPE_ 2457272390 tle_3_ecc : 1;
SIG_VALTYPE_ 2457272390 tle_3_inc : 1;
SIG_VALTYPE_ 2457272389 tle_2_day : 2;
SIG_VALTYPE_ 2449932356 tle_1_mna : 1;
SIG_VALTYPE_ 2449932356 tle_1_bstar : 1;
